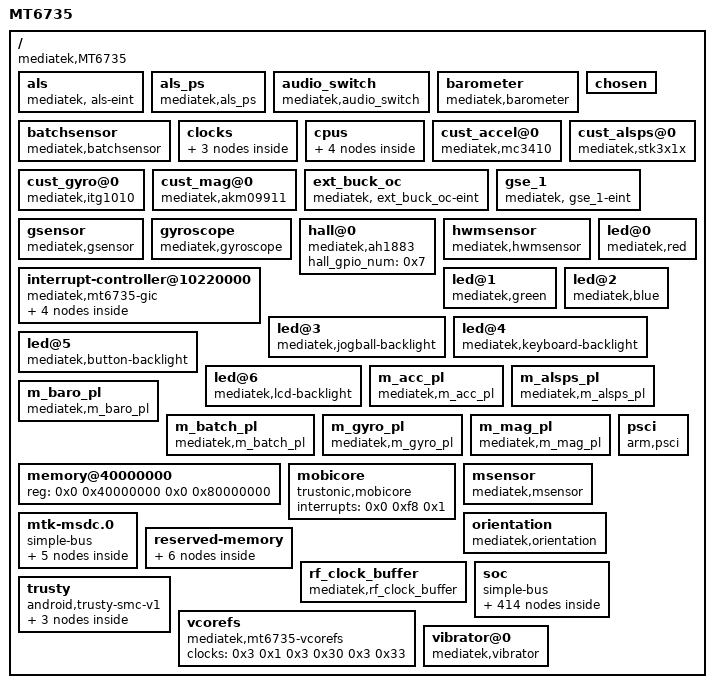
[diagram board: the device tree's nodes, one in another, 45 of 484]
/dts-v1/;

/ {
	#address-cells = <0x2>;
	#size-cells = <0x2>;
	compatible = "mediatek,MT6735";
	interrupt-parent = <0x1>;
	model = "MT6735";

	als {
		compatible = "mediatek, als-eint";
		debounce = <0x3 0x0>;
		interrupt-parent = <0xc>;
		interrupts = <0x3 0x8>;
		status = "okay";
	};

	als_ps {
		compatible = "mediatek,als_ps";
		pinctrl-0 = <0x90>;
		pinctrl-1 = <0x91>;
		pinctrl-names = "pin_default", "pin_cfg";
		status = "okay";
	};

	audio_switch {
		compatible = "mediatek,audio_switch";
	};

	barometer {
		compatible = "mediatek,barometer";
	};

	batchsensor {
		compatible = "mediatek,batchsensor";
	};

	chosen {
		bootargs = "console=tty0 console=ttyMT0,921600n1 root=/dev/ram initrd=0x44000000,0x300000 loglevel=8 androidboot.hardware=mt6735";
	};

	clocks {

		clk26m {
			#clock-cells = <0x0>;
			clock-frequency = <0x18cba80>;
			compatible = "fixed-clock";
			linux,phandle = <0x3b>;
			phandle = <0x3b>;
		};

		clk32k {
			#clock-cells = <0x0>;
			clock-frequency = <0x7d00>;
			compatible = "fixed-clock";
		};

		clk_null {
			#clock-cells = <0x0>;
			clock-frequency = <0x0>;
			compatible = "fixed-clock";
		};
	};

	cpus {
		#address-cells = <0x1>;
		#size-cells = <0x0>;

		cpu@000 {
			clock-frequency = "M|m";
			compatible = "arm,cortex-a53";
			cpu-release-addr = <0x0 0x40000200>;
			device_type = "cpu";
			enable-method = "spin-table";
			linux,phandle = <0xd>;
			phandle = <0xd>;
			reg = <0x0>;
		};

		cpu@001 {
			clock-frequency = "M|m";
			compatible = "arm,cortex-a53";
			cpu-release-addr = <0x0 0x40000200>;
			device_type = "cpu";
			enable-method = "spin-table";
			linux,phandle = <0xe>;
			phandle = <0xe>;
			reg = <0x1>;
		};

		cpu@002 {
			clock-frequency = "M|m";
			compatible = "arm,cortex-a53";
			cpu-release-addr = <0x0 0x40000200>;
			device_type = "cpu";
			enable-method = "spin-table";
			linux,phandle = <0xf>;
			phandle = <0xf>;
			reg = <0x2>;
		};

		cpu@003 {
			clock-frequency = "M|m";
			compatible = "arm,cortex-a53";
			cpu-release-addr = <0x0 0x40000200>;
			device_type = "cpu";
			enable-method = "spin-table";
			linux,phandle = <0x10>;
			phandle = <0x10>;
			reg = <0x3>;
		};
	};

	cust_accel@0 {
		compatible = "mediatek,mc3410";
		direction = <0x0>;
		firlen = <0x0>;
		i2c_addr = <0x4c 0x0 0x0 0x0>;
		i2c_num = <0x2>;
		is_batch_supported = <0x0>;
		power_id = <0xffff>;
		power_vol = <0x0>;
	};

	cust_alsps@0 {
		als_level = <0x5 0x9 0x24 0x3b 0x52 0x84 0xcd 0x111 0x1f4 0x34d 0x470 0x609 0x93c 0x122f 0x1b46>;
		als_value = <0xa 0xa 0x50 0x55 0x5a 0x91 0xe1 0x12c 0x226 0x3a2 0x4e2 0x6a4 0xa28 0x1400 0x1e00 0x2800>;
		compatible = "mediatek,stk3x1x";
		i2c_addr = <0x48 0x0 0x0 0x0>;
		i2c_num = <0x2>;
		is_batch_supported_als = <0x0>;
		is_batch_supported_ps = <0x0>;
		polling_mode_als = <0x1>;
		polling_mode_ps = <0x0>;
		power_id = <0xffff>;
		power_vol = <0x0>;
		ps_threshold_high = <0x6a4>;
		ps_threshold_low = <0x5dc>;
	};

	cust_gyro@0 {
		compatible = "mediatek,itg1010";
		direction = <0x3>;
		firlen = <0x0>;
		i2c_addr = <0x68 0x0 0x0 0x0>;
		i2c_num = <0x2>;
		is_batch_supported = <0x0>;
		power_id = <0xffff>;
		power_vol = <0x0>;
	};

	cust_mag@0 {
		compatible = "mediatek,akm09911";
		direction = <0x2>;
		i2c_addr = <0xd 0x0 0x0 0x0>;
		i2c_num = <0x2>;
		is_batch_supported = <0x0>;
		power_id = <0xffff>;
		power_vol = <0x0>;
	};

	ext_buck_oc {
		compatible = "mediatek, ext_buck_oc-eint";
		debounce = <0x4e 0x0>;
		interrupt-parent = <0xc>;
		interrupts = <0x4e 0x4>;
		status = "okay";
	};

	gse_1 {
		compatible = "mediatek, gse_1-eint";
		debounce = <0x42 0x0>;
		interrupt-parent = <0xc>;
		interrupts = <0x42 0x8>;
		status = "okay";
	};

	gsensor {
		compatible = "mediatek,gsensor";
	};

	gyroscope {
		compatible = "mediatek,gyroscope";
		debounce = <0x43 0x0>;
		interrupt-parent = <0xc>;
		interrupts = <0x43 0x8>;
		pinctrl-0 = <0x92>;
		pinctrl-1 = <0x93>;
		pinctrl-names = "pin_default", "pin_cfg";
		status = "okay";
	};

	hall@0 {
		compatible = "mediatek,ah1883";
		hall_gpio_num = <0x7>;
	};

	hwmsensor {
		compatible = "mediatek,hwmsensor";
	};

	interrupt-controller@10220000 {
		#address-cells = <0x0>;
		#interrupt-cells = <0x3>;
		compatible = "mediatek,mt6735-gic";
		interrupt-controller;
		linux,phandle = <0x1>;
		mediatek,wdt_irq = <0xa0>;
		phandle = <0x1>;
		reg = <0x0 0x10221000 0x0 0x1000 0x0 0x10222000 0x0 0x1000 0x0 0x10200620 0x0 0x1000>;

		gic-cpuif@0 {
			compatible = "arm,gic-cpuif";
			cpu = <0xd>;
			cpuif-id = <0x0>;
		};

		gic-cpuif@1 {
			compatible = "arm,gic-cpuif";
			cpu = <0xe>;
			cpuif-id = <0x1>;
		};

		gic-cpuif@2 {
			compatible = "arm,gic-cpuif";
			cpu = <0xf>;
			cpuif-id = <0x2>;
		};

		gic-cpuif@3 {
			compatible = "arm,gic-cpuif";
			cpu = <0x10>;
			cpuif-id = <0x3>;
		};
	};

	led@0 {
		compatible = "mediatek,red";
		data = <0x1>;
		led_mode = <0x0>;
		pwm_config = <0x0 0x0 0x0 0x0 0x0>;
	};

	led@1 {
		compatible = "mediatek,green";
		data = <0x1>;
		led_mode = <0x0>;
		pwm_config = <0x0 0x0 0x0 0x0 0x0>;
	};

	led@2 {
		compatible = "mediatek,blue";
		data = <0x1>;
		led_mode = <0x0>;
		pwm_config = <0x0 0x0 0x0 0x0 0x0>;
	};

	led@3 {
		compatible = "mediatek,jogball-backlight";
		data = <0x1>;
		led_mode = <0x0>;
		pwm_config = <0x0 0x0 0x0 0x0 0x0>;
	};

	led@4 {
		compatible = "mediatek,keyboard-backlight";
		data = <0x1>;
		led_mode = <0x0>;
		pwm_config = <0x0 0x0 0x0 0x0 0x0>;
	};

	led@5 {
		compatible = "mediatek,button-backlight";
		data = <0x1>;
		led_mode = <0x3>;
		pwm_config = <0x0 0x0 0x0 0x0 0x0>;
	};

	led@6 {
		compatible = "mediatek,lcd-backlight";
		data = <0x1>;
		led_mode = <0x5>;
		pwm_config = <0x0 0x0 0x0 0x0 0x0>;
	};

	m_acc_pl {
		compatible = "mediatek,m_acc_pl";
	};

	m_alsps_pl {
		compatible = "mediatek,m_alsps_pl";
	};

	m_baro_pl {
		compatible = "mediatek,m_baro_pl";
	};

	m_batch_pl {
		compatible = "mediatek,m_batch_pl";
	};

	m_gyro_pl {
		compatible = "mediatek,m_gyro_pl";
	};

	m_mag_pl {
		compatible = "mediatek,m_mag_pl";
	};

	memory@40000000 {
		device_type = "memory";
		reg = <0x0 0x40000000 0x0 0x80000000>;
	};

	mobicore {
		compatible = "trustonic,mobicore";
		interrupts = <0x0 0xf8 0x1>;
	};

	msensor {
		compatible = "mediatek,msensor";
	};

	mtk-msdc.0 {
		#address-cells = <0x1>;
		#size-cells = <0x1>;
		compatible = "simple-bus";
		ranges = <0x0 0x0 0x0 0xffffffff>;

		default {
			compatible = "mediatek, msdc1_ins-eint";
			debounce = <0x5 0x1f400>;
			interrupt-parent = <0xc>;
			interrupts = <0x5 0x4>;
			status = "okay";
		};

		msdc0@11230000 {
			bootable;
			bus-width = <0x8>;
			cap-mmc-highspeed;
			clk_src = [02];
			clock-names = "MSDC0-CLOCK", "MSDC0_PLL_SEL", "MSDC0_PLL_800M", "MSDC0_PLL_400M", "MSDC0_PLL_200M";
			clocks = <0x2 0xe 0x3 0xd 0x3 0x29 0x3 0x2b 0x3 0x2c>;
			compatible = "mediatek,mt6735-mmc";
			host_function = [00];
			interrupts = <0x0 0x4f 0x8>;
			max-frequency = <0xbebc200>;
			mmc-ddr-1_8v;
			mmc-hs200-1_8v;
			mmc-hs400-1_8v;
			msdc-sys-suspend;
			non-removable;
			pinctl = <0x4>;
			reg = <0x11230000 0x10000 0x10000e84 0x2>;
			register_setting = <0x5>;
			status = "okay";
		};

		msdc1@11240000 {
			bus-width = <0x4>;
			cap-sd-highspeed;
			cd-gpios = <0xb 0x5 0x0>;
			cd_level = [00];
			clk_src = [02];
			clock-names = "MSDC1-CLOCK";
			clocks = <0x2 0xf>;
			compatible = "mediatek,mt6735-mmc";
			host_function = [01];
			interrupts = <0x0 0x50 0x8>;
			max-frequency = <0xbebc200>;
			msdc-sys-suspend;
			pinctl = <0x6>;
			pinctl_ddr50 = <0x9>;
			pinctl_sdr104 = <0x7>;
			pinctl_sdr50 = <0x8>;
			reg = <0x11240000 0x10000 0x10000e84 0x2>;
			register_setting = <0xa>;
			sd-uhs-ddr50;
			sd-uhs-sdr104;
			sd-uhs-sdr12;
			sd-uhs-sdr25;
			sd-uhs-sdr50;
			status = "okay";
		};

		msdc2@11250000 {
			clock-names = "MSDC2-CLOCK";
			clocks = <0x2 0x10>;
			compatible = "mediatek,mt6735-mmc";
			interrupts = <0x0 0x51 0x8>;
			reg = <0x11250000 0x10000 0x10000e84 0x2>;
			status = "disabled";
		};

		msdc3@11260000 {
			clock-names = "MSDC3-CLOCK";
			clocks = <0x2 0x11>;
			compatible = "mediatek,mt6735-mmc";
			interrupts = <0x0 0x52 0x8>;
			reg = <0x11260000 0x10000 0x10000e84 0x2>;
			status = "disabled";
		};
	};

	orientation {
		compatible = "mediatek,orientation";
	};

	psci {
		affinity_info = <0x84000004>;
		compatible = "arm,psci";
		cpu_off = <0x84000002>;
		cpu_on = <0x84000003>;
		cpu_suspend = <0x84000001>;
		method = "smc";
	};

	reserved-memory {
		#address-cells = <0x2>;
		#size-cells = <0x2>;
		ranges;

		atf-reserved-memory@43000000 {
			compatible = "mediatek,mt6735-atf-reserved-memory", "mediatek,mt6735m-atf-reserved-memory", "mediatek,mt6753-atf-reserved-memory";
			no-map;
			reg = <0x0 0x43000000 0x0 0x30000>;
		};

		consys-reserve-memory {
			alignment = <0x0 0x200000>;
			compatible = "mediatek,consys-reserve-memory";
			no-map;
			size = <0x0 0x100000>;
		};

		minirdump-reserved-memory@43ff0000 {
			compatible = "mediatek,minirdump";
			reg = <0x0 0x43ff0000 0x0 0x10000>;
		};

		pstore-reserved-memory@43f10000 {
			compatible = "mediatek,pstore";
			reg = <0x0 0x43f10000 0x0 0xe0000>;
		};

		ram_console-reserved-memory@43f00000 {
			compatible = "mediatek,ram_console";
			reg = <0x0 0x43f00000 0x0 0x10000>;
		};

		reserve-memory-ccci_md1 {
			alignment = <0x0 0x2000000>;
			alloc-ranges = <0x0 0x40000000 0x0 0xc0000000>;
			compatible = "mediatek,reserve-memory-ccci_md1";
			no-map;
			size = <0x0 0x3810000>;
		};
	};

	rf_clock_buffer {
		compatible = "mediatek,rf_clock_buffer";
		mediatek,clkbuf-config = <0x2 0x2 0x2 0x2>;
		mediatek,clkbuf-quantity = <0x4>;
		status = "okay";
	};

	soc {
		#address-cells = <0x1>;
		#size-cells = <0x1>;
		compatible = "simple-bus";
		ranges = <0x0 0x0 0x0 0xffffffff>;

		BAT_NOTIFY {
			compatible = "mediatek,bat_notify";
		};

		accdet {
			accdet-mic-mode = <0x1>;
			accdet-mic-vol = <0x7>;
			accdet-plugout-debounce = <0x14>;
			compatible = "mediatek,mt6735-accdet";
			debounce = <0x6 0x3e800>;
			headset-four-key-threshold = <0x0 0x3a 0x79 0xc0 0x1c2>;
			headset-mode-setting = <0x500 0x200 0x1 0x1f0 0x800 0x800 0x20>;
			headset-three-key-threshold = <0x0 0x50 0xdc 0x1f4>;
			interrupt-parent = <0xc>;
			interrupts = <0x6 0x8>;
			pinctrl-0 = <0x63>;
			pinctrl-1 = <0x64>;
			pinctrl-names = "default", "state_eint_as_int1";
			status = "okay";
		};

		adc_hw@11001000 {
			clock-names = "auxadc-main";
			clocks = <0x2 0x1c>;
			compatible = "mediatek,mt6735-auxadc";
			interrupts = <0x0 0x4c 0x2>;
			reg = <0x11001000 0x1000>;

			adc_channel@ {
				compatible = "mediatek,adc_channel";
				mediatek,adc_fdd_rf_params_dynamic_custom_ch = <0xc>;
				mediatek,temperature0 = <0x0>;
				mediatek,temperature1 = <0x1>;
				status = "okay";
			};
		};

		apmixed@10209000 {
			compatible = "mediatek,apmixed";
			reg = <0x10209000 0x1000>;
		};

		apmixedsys@10209000 {
			#clock-cells = <0x1>;
			compatible = "mediatek,mt6735-apmixedsys";
			linux,phandle = <0x3a>;
			phandle = <0x3a>;
			reg = <0x10209000 0x1000>;
		};

		apuart0@11002000 {
			cell-index = <0x0>;
			clock-div = <0x1>;
			clock-frequency = <0x18cba80>;
			clock-names = "uart0-main", "uart-apdma";
			clocks = <0x2 0x12 0x2 0xd>;
			compatible = "mediatek,mt6735-uart";
			interrupts = <0x0 0x5b 0x8 0x0 0x67 0x8 0x0 0x68 0x8>;
			pinctrl-0 = <0x1f>;
			pinctrl-1 = <0x20>;
			pinctrl-2 = <0x21>;
			pinctrl-3 = <0x22>;
			pinctrl-4 = <0x23>;
			pinctrl-names = "uart0_gpio_default", "uart0_rx_set", "uart0_rx_clear", "uart0_tx_set", "uart0_tx_clear";
			reg = <0x11002000 0x1000 0x11000380 0x1000 0x11000400 0x80>;
			status = "okay";
		};

		apuart1@11003000 {
			cell-index = <0x1>;
			clock-div = <0x1>;
			clock-frequency = <0x18cba80>;
			clock-names = "uart1-main";
			clocks = <0x2 0x13>;
			compatible = "mediatek,mt6735-uart";
			interrupts = <0x0 0x5c 0x8 0x0 0x69 0x8 0x0 0x6a 0x8>;
			pinctrl-0 = <0x24>;
			pinctrl-1 = <0x25>;
			pinctrl-2 = <0x26>;
			pinctrl-3 = <0x27>;
			pinctrl-4 = <0x28>;
			pinctrl-names = "uart1_gpio_default", "uart1_rx_set", "uart1_rx_clear", "uart1_tx_set", "uart1_tx_clear";
			reg = <0x11003000 0x1000 0x11000480 0x80 0x11000500 0x80>;
			status = "okay";
		};

		apuart2@11004000 {
			cell-index = <0x2>;
			clock-div = <0x1>;
			clock-frequency = <0x18cba80>;
			clock-names = "uart2-main";
			clocks = <0x2 0x14>;
			compatible = "mediatek,mt6735-uart";
			interrupts = <0x0 0x5d 0x8 0x0 0x6b 0x8 0x0 0x6c 0x8>;
			pinctrl-0 = <0x29>;
			pinctrl-1 = <0x2a>;
			pinctrl-2 = <0x2b>;
			pinctrl-3 = <0x2c>;
			pinctrl-4 = <0x2d>;
			pinctrl-names = "uart2_gpio_default", "uart2_rx_set", "uart2_rx_clear", "uart2_tx_set", "uart2_tx_clear";
			reg = <0x11004000 0x1000 0x11000580 0x80 0x11000600 0x80>;
			status = "okay";
		};

		apuart3@11005000 {
			cell-index = <0x3>;
			clock-div = <0x1>;
			clock-frequency = <0x18cba80>;
			clock-names = "uart3-main";
			clocks = <0x2 0x15>;
			compatible = "mediatek,mt6735-uart";
			interrupts = <0x0 0x5e 0x8 0x0 0x6d 0x8 0x0 0x6e 0x8>;
			pinctrl-0 = <0x2e>;
			pinctrl-1 = <0x2f>;
			pinctrl-2 = <0x30>;
			pinctrl-3 = <0x31>;
			pinctrl-4 = <0x32>;
			pinctrl-names = "uart3_gpio_default", "uart3_rx_set", "uart3_rx_clear", "uart3_tx_set", "uart3_tx_clear";
			reg = <0x11005000 0x1000 0x11000680 0x80 0x11000700 0x80>;
			status = "okay";
		};

		apuart4@1100D000 {
			cell-index = <0x4>;
			clock-div = <0x1>;
			clock-frequency = <0x18cba80>;
			clock-names = "uart4-main";
			clocks = <0x2 0x16>;
			compatible = "mediatek,mt6735-uart";
			interrupts = <0x0 0x5f 0x8 0x0 0x6f 0x8 0x0 0x70 0x8>;
			reg = <0x1100d000 0x1000 0x11000780 0x80 0x11000800 0x80>;
		};

		apxgpt@10004000 {
			clock-frequency = <0xc65d40>;
			compatible = "mediatek,mt6735-apxgpt";
			interrupts = <0x0 0x98 0x8>;
			reg = <0x10004000 0x1000>;
		};

		audio@11220000 {
			compatible = "mediatek,audio";
			interrupts = <0x0 0x90 0x8>;
			reg = <0x11220000 0x10000>;
		};

		audiosys@11220000 {
			#clock-cells = <0x1>;
			compatible = "mediatek,mt6735-audiosys";
			linux,phandle = <0x39>;
			phandle = <0x39>;
			reg = <0x11220000 0x10000>;
		};

		bat_comm {
			ac_charger_current = <0x3d090>;
			apple_0_5a_charger_current = <0xc350>;
			apple_1_0a_charger_current = <0xfde8>;
			apple_2_1a_charger_current = <0x13880>;
			bat_low_temp_protect_enable = <0x0>;
			charging_full_current = <0x64>;
			charging_host_charger_current = <0xfde8>;
			compatible = "mediatek,battery";
			config_usb_if = <0x0>;
			err_charge_temperature = <0xff>;
			high_battery_voltage_support = <0x1>;
			max_charge_temperature = <0x46>;
			max_charge_temperature_minus_x_degree = <0x2f>;
			min_charge_temperature = <0x0>;
			min_charge_temperature_plus_x_degree = <0x6>;
			mtk_pump_express_plus_support = <0x1>;
			mtk_temperature_recharge_support = <0x1>;
			non_std_ac_charger_current = <0xc350>;
			npercent_tracking_time = <0x14>;
			onehundred_percent_tracking_time = <0xa>;
			recharging_voltage = <0x107c>;
			stop_charging_in_takling = <0x1>;
			sync_to_real_tracking_time = <0x3c>;
			ta_9v_support = <0x1>;
			ta_ac_7v_input_current = <0x30d40>;
			ta_ac_9v_input_current = <0x30d40>;
			ta_ac_charging_current = <0x3d090>;
			ta_start_battery_soc = <0x1>;
			ta_stop_battery_soc = <0x5f>;
			talking_recharge_voltage = <0xed8>;
			talking_sync_time = <0x3c>;
			usb_charger_current = <0xc350>;
			usb_charger_current_configured = <0xc350>;
			usb_charger_current_suspend = <0x0>;
			usb_charger_current_unconfigured = <0x1b58>;
			v_0percent_tracking = <0xd7a>;
			v_cc2topoff_thres = <0x1040>;
			v_charger_enable = <0x0>;
			v_charger_max = <0x2904>;
			v_charger_min = <0x1130>;
			v_pre2cc_thres = <0xd48>;
		};

		bat_meter {
			aging_tuning_value = <0x67>;
			batt_temperature_table = <0xffffffec 0x10a8d 0xfffffff1 0xd192 0xfffffff6 0xa60a 0xfffffffb 0x8464 0x0 0x6a53 0x5 0x5605 0xa 0x4606 0xf 0x3952 0x14 0x2f31 0x19 0x2710 0x1e 0x207b 0x23 0x1b24 0x28 0x16ca 0x2d 0x1335 0x32 0x1041 0x37 0xdcf 0x3c 0xbc6 0x41 0xa28 0x46 0x8ca>;
			batt_temperature_table_num = <0x13>;
			battery_profile_t0 = <0x0 0x10e4 0x2 0x10c2 0x4 0x10a8 0x6 0x1091 0x8 0x107c 0x9 0x1068 0xb 0x1054 0xd 0x1041 0xf 0x102e 0x11 0x101b 0x13 0x1009 0x15 0xffa 0x17 0xfed 0x18 0xfd9 0x1a 0xfba 0x1c 0xf9a 0x1e 0xf83 0x20 0xf71 0x22 0xf63 0x24 0xf57 0x26 0xf4b 0x27 0xf3f 0x29 0xf32 0x2b 0xf26 0x2d 0xf1a 0x2f 0xf0f 0x31 0xf04 0x33 0xefb 0x35 0xef2 0x36 0xeeb 0x38 0xee3 0x3a 0xedd 0x3c 0xed7 0x3e 0xed1 0x40 0xecd 0x42 0xeca 0x44 0xec7 0x45 0xec5 0x47 0xec2 0x49 0xebf 0x4b 0xebc 0x4d 0xeb8 0x4f 0xeb4 0x51 0xeaf 0x53 0xea8 0x54 0xea1 0x56 0xe97 0x58 0xe8e 0x5a 0xe83 0x5c 0xe79 0x5e 0xe70 0x60 0xe68 0x61 0xe61 0x62 0xe5a 0x63 0xe50 0x64 0xdc8 0x64 0xdac 0x64 0xdac 0x64 0xdac 0x64 0xdac 0x64 0xdac 0x64 0xdac 0x64 0xdac 0x64 0xdac 0x64 0xdac 0x64 0xdac 0x64 0xdac 0x64 0xdac 0x64 0xdac 0x64 0xdac 0x64 0xdac 0x64 0xdac 0x64 0xdac 0x64 0xdac 0x64 0xdac 0x64 0xdac 0x64 0xdac 0x64 0xdac 0x64 0xdac 0x64 0xdac 0x64 0xdac 0x64 0xdac 0x64 0xdac 0x64 0xdac 0x64 0xdac 0x64 0xdac 0x64 0xdac 0x64 0xdac 0x64 0xdac 0x64 0xdac 0x64 0xdac 0x64 0xdac 0x64 0xdac 0x64 0xdac 0x64 0xdac 0x64 0xdac 0x64 0xdac 0x64 0xdac 0x64 0xdac 0x64 0xdac>;
			battery_profile_t0_num = <0x64>;
			battery_profile_t1 = <0x0 0x10e9 0x2 0x10cd 0x4 0x10b4 0x6 0x10a0 0x7 0x108c 0x9 0x1078 0xb 0x1065 0xd 0x1052 0xf 0x103f 0x11 0x102c 0x12 0x1018 0x14 0x1006 0x16 0xff5 0x18 0xfea 0x1a 0xfdc 0x1c 0xfbc 0x1e 0xf98 0x1f 0xf82 0x21 0xf72 0x23 0xf66 0x25 0xf5b 0x27 0xf4e 0x29 0xf3f 0x2b 0xf31 0x2c 0xf23 0x2e 0xf16 0x30 0xf0b 0x32 0xf01 0x34 0xef8 0x36 0xef0 0x37 0xee8 0x39 0xee2 0x3b 0xedb 0x3d 0xed5 0x3f 0xed0 0x41 0xecb 0x43 0xec7 0x44 0xec3 0x46 0xec0 0x48 0xebe 0x4a 0xeba 0x4c 0xeb7 0x4e 0xeb2 0x4f 0xead 0x51 0xea6 0x53 0xe9e 0x55 0xe93 0x57 0xe89 0x59 0xe7b 0x5b 0xe72 0x5c 0xe6e 0x5e 0xe69 0x60 0xe5c 0x62 0xe28 0x64 0xdbb 0x64 0xdac 0x64 0xdac 0x64 0xdac 0x64 0xdac 0x64 0xdac 0x64 0xdac 0x64 0xdac 0x64 0xdac 0x64 0xdac 0x64 0xdac 0x64 0xdac 0x64 0xdac 0x64 0xdac 0x64 0xdac 0x64 0xdac 0x64 0xdac 0x64 0xdac 0x64 0xdac 0x64 0xdac 0x64 0xdac 0x64 0xdac 0x64 0xdac 0x64 0xdac 0x64 0xdac 0x64 0xdac 0x64 0xdac 0x64 0xdac 0x64 0xdac 0x64 0xdac 0x64 0xdac 0x64 0xdac 0x64 0xdac 0x64 0xdac 0x64 0xdac 0x64 0xdac 0x64 0xdac 0x64 0xdac 0x64 0xdac 0x64 0xdac 0x64 0xdac 0x64 0xdac 0x64 0xdac 0x64 0xdac 0x64 0xdac 0x64 0xdac>;
			battery_profile_t1_num = <0x64>;
			battery_profile_t2 = <0x0 0x10f1 0x2 0x10d8 0x4 0x10c1 0x5 0x10ac 0x7 0x1097 0x9 0x1083 0xb 0x106e 0xd 0x105b 0xf 0x1047 0x10 0x1034 0x12 0x1021 0x14 0x100e 0x16 0xffb 0x18 0xfe9 0x19 0xfde 0x1b 0xfcf 0x1d 0xfb1 0x1f 0xf98 0x21 0xf8b 0x23 0xf84 0x24 0xf79 0x26 0xf6b 0x28 0xf5d 0x2a 0xf4c 0x2c 0xf37 0x2d 0xf24 0x2f 0xf16 0x31 0xf0a 0x33 0xf00 0x35 0xef7 0x37 0xeef 0x38 0xee8 0x3a 0xee1 0x3c 0xeda 0x3e 0xed5 0x40 0xecf 0x41 0xeca 0x43 0xec6 0x45 0xec1 0x47 0xebc 0x49 0xeb5 0x4b 0xead 0x4c 0xea8 0x4e 0xea1 0x50 0xe9b 0x52 0xe96 0x54 0xe8e 0x55 0xe83 0x57 0xe79 0x59 0xe6b 0x5b 0xe64 0x5d 0xe62 0x5f 0xe61 0x60 0xe58 0x62 0xe1b 0x64 0xdac 0x64 0xdac 0x64 0xdac 0x64 0xdac 0x64 0xdac 0x64 0xdac 0x64 0xdac 0x64 0xdac 0x64 0xdac 0x64 0xdac 0x64 0xdac 0x64 0xdac 0x64 0xdac 0x64 0xdac 0x64 0xdac 0x64 0xdac 0x64 0xdac 0x64 0xdac 0x64 0xdac 0x64 0xdac 0x64 0xdac 0x64 0xdac 0x64 0xdac 0x64 0xdac 0x64 0xdac 0x64 0xdac 0x64 0xdac 0x64 0xdac 0x64 0xdac 0x64 0xdac 0x64 0xdac 0x64 0xdac 0x64 0xdac 0x64 0xdac 0x64 0xdac 0x64 0xdac 0x64 0xdac 0x64 0xdac 0x64 0xdac 0x64 0xdac 0x64 0xdac 0x64 0xdac 0x64 0xdac 0x64 0xdac 0x64 0xdac>;
			battery_profile_t2_num = <0x64>;
			battery_profile_t3 = <0x0 0x10d9 0x2 0x10c2 0x4 0x10ad 0x6 0x1098 0x8 0x1083 0x9 0x106f 0xb 0x105a 0xd 0x1046 0xf 0x1033 0x11 0x101f 0x13 0x100c 0x15 0xff9 0x17 0xfe7 0x19 0xfd5 0x1a 0xfc4 0x1c 0xfb3 0x1e 0xfa2 0x20 0xf93 0x22 0xf83 0x24 0xf73 0x26 0xf63 0x28 0xf50 0x29 0xf3c 0x2b 0xf2a 0x2d 0xf1c 0x2f 0xf11 0x31 0xf06 0x33 0xefd 0x35 0xef4 0x37 0xeec 0x39 0xee4 0x3a 0xedd 0x3c 0xed7 0x3e 0xed0 0x40 0xecb 0x42 0xec6 0x44 0xec0 0x46 0xeba 0x48 0xeae 0x4a 0xea4 0x4b 0xe9d 0x4d 0xe95 0x4f 0xe8e 0x51 0xe89 0x53 0xe81 0x55 0xe76 0x57 0xe6c 0x59 0xe5f 0x5b 0xe59 0x5c 0xe58 0x5e 0xe56 0x60 0xe4d 0x62 0xe15 0x64 0xdb2 0x64 0xdac 0x64 0xdac 0x64 0xdac 0x64 0xdac 0x64 0xdac 0x64 0xdac 0x64 0xdac 0x64 0xdac 0x64 0xdac 0x64 0xdac 0x64 0xdac 0x64 0xdac 0x64 0xdac 0x64 0xdac 0x64 0xdac 0x64 0xdac 0x64 0xdac 0x64 0xdac 0x64 0xdac 0x64 0xdac 0x64 0xdac 0x64 0xdac 0x64 0xdac 0x64 0xdac 0x64 0xdac 0x64 0xdac 0x64 0xdac 0x64 0xdac 0x64 0xdac 0x64 0xdac 0x64 0xdac 0x64 0xdac 0x64 0xdac 0x64 0xdac 0x64 0xdac 0x64 0xdac 0x64 0xdac 0x64 0xdac 0x64 0xdac 0x64 0xdac 0x64 0xdac 0x64 0xdac 0x64 0xdac 0x64 0xdac 0x64 0xdac 0x64 0xdac>;
			battery_profile_t3_num = <0x64>;
			car_tune_value = <0x5f>;
			change_tracking_point = <0x1>;
			close_poweroff_wakeup_period = <0x1e>;
			compatible = "mediatek,bat_meter";
			current_detect_r_fg = <0xa>;
			cust_hw_cc = <0x0>;
			cust_poweron_delta_capacity_tolrance = <0x1e>;
			cust_poweron_delta_hw_sw_ocv_capacity_tolrance = <0xa>;
			cust_poweron_delta_vbat_tolrance = <0x1e>;
			cust_poweron_low_capacity_tolrance = <0x5>;
			cust_poweron_max_vbat_tolrance = <0x5a>;
			cust_r_fg_offset = <0x0>;
			cust_r_sense = <0x44>;
			cust_tracking_point = <0x1>;
			fg_meter_resistance = <0x0>;
			fg_vbat_average_size = <0x12>;
			fixed_tbat_25 = <0x0>;
			low_power_wakeup_period = <0x12c>;
			minerroroffset = <0x3e8>;
			normal_wakeup_period = <0x1518>;
			oam_d5 = <0x1>;
			ocv_board_compesate = <0x0>;
			q_max_neg_10 = <0x11e3>;
			q_max_neg_10_h_current = <0xdd0>;
			q_max_pos_0 = <0x13b2>;
			q_max_pos_0_h_current = <0x1279>;
			q_max_pos_25 = <0x13ec>;
			q_max_pos_25_h_current = <0x13ba>;
			q_max_pos_50 = <0x1359>;
			q_max_pos_50_h_current = <0x132f>;
			r_bat_sense = <0x4>;
			r_charger_1 = <0x14a>;
			r_charger_2 = <0x27>;
			r_fg_board_base = <0x3e8>;
			r_fg_board_slope = <0x3e8>;
			r_fg_value = <0xa>;
			r_i_sense = <0x4>;
			r_profile_t0 = <0x351 0x10e4 0x351 0x10c2 0x34b 0x10a8 0x344 0x1091 0x334 0x107c 0x32b 0x1068 0x31f 0x1054 0x315 0x1041 0x30c 0x102e 0x301 0x101b 0x2f7 0x1009 0x2f4 0xffa 0x2f5 0xfed 0x2ed 0xfd9 0x2d0 0xfba 0x2b2 0xf9a 0x2a5 0xf83 0x29f 0xf71 0x29c 0xf63 0x29c 0xf57 0x296 0xf4b 0x28d 0xf3f 0x28d 0xf32 0x287 0xf26 0x283 0xf1a 0x27e 0xf0f 0x27e 0xf04 0x27e 0xefb 0x27e 0xef2 0x27e 0xeeb 0x281 0xee3 0x283 0xedd 0x286 0xed7 0x289 0xed1 0x28e 0xecd 0x295 0xeca 0x29f 0xec7 0x2af 0xec5 0x2bb 0xec2 0x2cb 0xebf 0x2da 0xebc 0x2ea 0xeb8 0x303 0xeb4 0x31b 0xeaf 0x337 0xea8 0x352 0xea1 0x379 0xe97 0x3a2 0xe8e 0x3d4 0xe83 0x67 0xe79 0x6e 0xe70 0x77 0xe68 0x78 0xe61 0x76 0xe5a 0x74 0xe50 0x335 0xdc8 0x335 0xdac 0x335 0xdac 0x335 0xdac 0x335 0xdac 0x335 0xdac 0x335 0xdac 0x335 0xdac 0x335 0xdac 0x335 0xdac 0x335 0xdac 0x335 0xdac 0x335 0xdac 0x335 0xdac 0x335 0xdac 0x335 0xdac 0x335 0xdac 0x335 0xdac 0x335 0xdac 0x335 0xdac 0x335 0xdac 0x335 0xdac 0x335 0xdac 0x335 0xdac 0x335 0xdac 0x335 0xdac 0x335 0xdac 0x335 0xdac 0x335 0xdac 0x335 0xdac 0x335 0xdac 0x335 0xdac 0x335 0xdac 0x335 0xdac 0x335 0xdac 0x335 0xdac 0x335 0xdac 0x335 0xdac 0x335 0xdac 0x335 0xdac 0x335 0xdac 0x335 0xdac 0x335 0xdac 0x335 0xdac 0x335 0xdac>;
			r_profile_t0_num = <0x64>;
			r_profile_t1 = <0x198 0x10e9 0x198 0x10cd 0x193 0x10b4 0x18d 0x10a0 0x186 0x108c 0x17e 0x1078 0x178 0x1065 0x173 0x1052 0x170 0x103f 0x16d 0x102c 0x169 0x1018 0x167 0x1006 0x166 0xff5 0x16d 0xfea 0x173 0xfdc 0x164 0xfbc 0x153 0xf98 0x14d 0xf82 0x149 0xf72 0x148 0xf66 0x147 0xf5b 0x13f 0xf4e 0x138 0xf3f 0x130 0xf31 0x12b 0xf23 0x128 0xf16 0x127 0xf0b 0x125 0xf01 0x126 0xef8 0x127 0xef0 0x128 0xee8 0x129 0xee2 0x12b 0xedb 0x12d 0xed5 0x12e 0xed0 0x130 0xecb 0x133 0xec7 0x137 0xec3 0x139 0xec0 0x138 0xebe 0x13c 0xeba 0x140 0xeb7 0x147 0xeb2 0x14c 0xead 0x154 0xea6 0x15c 0xe9e 0x166 0xe93 0x176 0xe89 0x188 0xe7b 0x19c 0xe72 0x1ba 0xe6e 0x1e6 0xe69 0x227 0xe5c 0x264 0xe28 0x2d7 0xdbb 0x2d7 0xdac 0x2d7 0xdac 0x2d7 0xdac 0x2d7 0xdac 0x2d7 0xdac 0x2d7 0xdac 0x2d7 0xdac 0x2d7 0xdac 0x2d7 0xdac 0x2d7 0xdac 0x2d7 0xdac 0x2d7 0xdac 0x2d7 0xdac 0x2d7 0xdac 0x2d7 0xdac 0x2d7 0xdac 0x2d7 0xdac 0x2d7 0xdac 0x2d7 0xdac 0x2d7 0xdac 0x2d7 0xdac 0x2d7 0xdac 0x2d7 0xdac 0x2d7 0xdac 0x2d7 0xdac 0x2d7 0xdac 0x2d7 0xdac 0x2d7 0xdac 0x2d7 0xdac 0x2d7 0xdac 0x2d7 0xdac 0x2d7 0xdac 0x2d7 0xdac 0x2d7 0xdac 0x2d7 0xdac 0x2d7 0xdac 0x2d7 0xdac 0x2d7 0xdac 0x2d7 0xdac 0x2d7 0xdac 0x2d7 0xdac 0x2d7 0xdac 0x2d7 0xdac 0x2d7 0xdac 0x2d7 0xdac>;
			r_profile_t1_num = <0x64>;
			r_profile_t2 = <0x7c 0x10f1 0x7c 0x10d8 0x7d 0x10c1 0x7b 0x10ac 0x7a 0x1097 0x7a 0x1083 0x7a 0x106e 0x7a 0x105b 0x79 0x1047 0x7b 0x1034 0x7d 0x1021 0x7c 0x100e 0x7c 0xffb 0x7c 0xfe9 0x85 0xfde 0x84 0xfcf 0x7d 0xfb1 0x7e 0xf98 0x80 0xf8b 0x88 0xf84 0x89 0xf79 0x8b 0xf6b 0x8d 0xf5d 0x8a 0xf4c 0x81 0xf37 0x7a 0xf24 0x77 0xf16 0x75 0xf0a 0x74 0xf00 0x74 0xef7 0x74 0xeef 0x75 0xee8 0x74 0xee1 0x73 0xeda 0x74 0xed5 0x74 0xecf 0x75 0xeca 0x76 0xec6 0x77 0xec1 0x77 0xebc 0x74 0xeb5 0x71 0xead 0x74 0xea8 0x74 0xea1 0x74 0xe9b 0x77 0xe96 0x76 0xe8e 0x76 0xe83 0x77 0xe79 0x77 0xe6b 0x74 0xe64 0x78 0xe62 0x81 0xe61 0x8c 0xe58 0x87 0xe1b 0x91 0xdac 0x91 0xdac 0x91 0xdac 0x91 0xdac 0x91 0xdac 0x91 0xdac 0x91 0xdac 0x91 0xdac 0x91 0xdac 0x91 0xdac 0x91 0xdac 0x91 0xdac 0x91 0xdac 0x91 0xdac 0x91 0xdac 0x91 0xdac 0x91 0xdac 0x91 0xdac 0x91 0xdac 0x91 0xdac 0x91 0xdac 0x91 0xdac 0x91 0xdac 0x91 0xdac 0x91 0xdac 0x91 0xdac 0x91 0xdac 0x91 0xdac 0x91 0xdac 0x91 0xdac 0x91 0xdac 0x91 0xdac 0x91 0xdac 0x91 0xdac 0x91 0xdac 0x91 0xdac 0x91 0xdac 0x91 0xdac 0x91 0xdac 0x91 0xdac 0x91 0xdac 0x91 0xdac 0x91 0xdac 0x91 0xdac 0x91 0xdac>;
			r_profile_t2_num = <0x64>;
			r_profile_t3 = <0x66 0x10d9 0x66 0x10c2 0x66 0x10ad 0x67 0x1098 0x67 0x1083 0x67 0x106f 0x66 0x105a 0x67 0x1046 0x67 0x1033 0x68 0x101f 0x68 0x100c 0x68 0xff9 0x69 0xfe7 0x6a 0xfd5 0x6c 0xfc4 0x6c 0xfb3 0x6d 0xfa2 0x70 0xf93 0x71 0xf83 0x73 0xf73 0x76 0xf63 0x74 0xf50 0x6d 0xf3c 0x69 0xf2a 0x67 0xf1c 0x68 0xf11 0x67 0xf06 0x67 0xefd 0x67 0xef4 0x66 0xeec 0x67 0xee4 0x68 0xedd 0x68 0xed7 0x69 0xed0 0x6a 0xecb 0x6c 0xec6 0x6d 0xec0 0x6d 0xeba 0x67 0xeae 0x68 0xea4 0x69 0xe9d 0x68 0xe95 0x67 0xe8e 0x6a 0xe89 0x6b 0xe81 0x69 0xe76 0x6b 0xe6c 0x67 0xe5f 0x66 0xe59 0x6d 0xe58 0x76 0xe56 0x7e 0xe4d 0x72 0xe15 0x77 0xdb2 0x89 0xdac 0x89 0xdac 0x89 0xdac 0x89 0xdac 0x89 0xdac 0x89 0xdac 0x89 0xdac 0x89 0xdac 0x89 0xdac 0x89 0xdac 0x89 0xdac 0x89 0xdac 0x89 0xdac 0x89 0xdac 0x89 0xdac 0x89 0xdac 0x89 0xdac 0x89 0xdac 0x89 0xdac 0x89 0xdac 0x89 0xdac 0x89 0xdac 0x89 0xdac 0x89 0xdac 0x89 0xdac 0x89 0xdac 0x89 0xdac 0x89 0xdac 0x89 0xdac 0x89 0xdac 0x89 0xdac 0x89 0xdac 0x89 0xdac 0x89 0xdac 0x89 0xdac 0x89 0xdac 0x89 0xdac 0x89 0xdac 0x89 0xdac 0x89 0xdac 0x89 0xdac 0x89 0xdac 0x89 0xdac 0x89 0xdac 0x89 0xdac 0x89 0xdac>;
			r_profile_t3_num = <0x64>;
			rbat_pull_up_r = <0x4204>;
			rbat_pull_up_volt = <0x708>;
			temperature_t = <0xff>;
			temperature_t0 = <0x6e>;
			temperature_t1 = <0x0>;
			temperature_t2 = <0x19>;
			temperature_t3 = <0x32>;
			vbat_low_power_wakeup = <0xdac>;
			vbat_normal_wakeup = <0xe10>;
		};

		btcvsd@18000000 {
			compatible = "mediatek,audio_bt_cvsd";
			interrupts = <0x0 0xe4 0x8>;
			offset = <0x700 0x800 0xfd0 0xfd4 0xfd8>;
			reg = <0x10000000 0x1000 0x18000000 0x10000 0x18080000 0x8000>;
		};

		btif@1100c000 {
			clock-names = "btifc", "apdmac";
			clocks = <0x2 0x17 0x2 0xd>;
			compatible = "mediatek,btif";
			interrupts = <0x0 0x5a 0x8>;
			reg = <0x1100c000 0x1000>;
		};

		btif_rx@11000900 {
			compatible = "mediatek,btif_rx";
			interrupts = <0x0 0x72 0x8>;
			reg = <0x11000900 0x80>;
		};

		btif_tx@11000880 {
			compatible = "mediatek,btif_tx";
			interrupts = <0x0 0x71 0x8>;
			reg = <0x11000880 0x80>;
		};

		bus_dbg@10208000 {
			compatible = "mediatek,bus_dbg-v1";
			interrupts = <0x0 0x89 0x8>;
			reg = <0x10208000 0x1000>;
		};

		c2k_sdio {
			compatible = "mediatek,mt6735-c2k_sdio";
			interrupts = <0x0 0xe6 0x8>;
		};

		ccci_off {
			clock-names = "scp-sys-md1-main";
			clocks = <0x11 0x1>;
			compatible = "mediatek,ccci_off";
		};

		chipid@08000000 {
			compatible = "mediatek,chipid";
			reg = <0x8000000 0x4 0x8000004 0x4 0x8000008 0x4 0x800000c 0x4>;
		};

		cksys@10210000 {
			compatible = "mediatek,cksys";
			reg = <0x10210000 0x1000>;
		};

		consys@18070000 {
			clock-names = "conn", "bus";
			clocks = <0x11 0x3 0x17 0xb>;
			compatible = "mediatek,mt6735-consys";
			interrupts = <0x0 0xe3 0x8 0x0 0xe1 0x8>;
			pinctrl-0 = <0x58>;
			pinctrl-1 = <0x59>;
			pinctrl-2 = <0x5a>;
			pinctrl-3 = <0x5b>;
			pinctrl-names = "default", "gps_lna_state_init", "gps_lna_state_oh", "gps_lna_state_ol";
			reg = <0x18070000 0x200 0x10212000 0x100 0x10000000 0x2000 0x10006000 0x1000>;
			status = "okay";
			vcn18-supply = <0x54>;
			vcn28-supply = <0x55>;
			vcn33_bt-supply = <0x56>;
			vcn33_wifi-supply = <0x57>;
		};

		cpu_dbgapb@0x10810000 {
			compatible = "mediatek,mt6735-dbg_debug";
			num = <0x4>;
			reg = <0x10810000 0x1000 0x10910000 0x1000 0x10a10000 0x1000 0x10b10000 0x1000>;
		};

		cpuxgpt@10200000 {
			compatible = "mediatek,mt6735-cpuxgpt";
			interrupts = <0x0 0x40 0x4 0x0 0x41 0x4 0x0 0x42 0x4 0x0 0x43 0x4 0x0 0x44 0x4 0x0 0x45 0x4 0x0 0x46 0x4 0x0 0x47 0x4>;
			reg = <0x10200000 0x1000>;
		};

		cqdma@10217c00 {
			compatible = "mediatek,cqdma";
			interrupts = <0x0 0x97 0x8>;
			nr_channel = <0x1>;
			reg = <0x10217c00 0xc00>;
		};

		dbgapb_base@1011a000 {
			compatible = "mediatek,dbgapb_base";
			reg = <0x1011a000 0x100>;
		};

		ddrphy@10213000 {
			compatible = "mediatek,mt6735-ddrphy";
			reg = <0x10213000 0x1000>;
		};

		devapc@10207000 {
			clock-names = "devapc-main";
			clocks = <0x17 0x5>;
			compatible = "mediatek,devapc";
			interrupts = <0x0 0x86 0x8>;
			reg = <0x10207000 0x1000>;
		};

		devapc_ao@10007000 {
			compatible = "mediatek,devapc_ao";
			reg = <0x10007000 0x1000>;
		};

		dispsys@14007000 {
			clock-names = "DISP0_SMI_COMMON", "DISP0_SMI_LARB0", "DISP0_DISP_OVL0", "DISP0_DISP_RDMA0", "DISP0_DISP_RDMA1", "DISP0_DISP_WDMA0", "DISP0_DISP_COLOR", "DISP0_DISP_CCORR", "DISP0_DISP_AAL", "DISP0_DISP_GAMMA", "DISP0_DISP_DITHER", "DISP1_DSI_ENGINE", "DISP1_DSI_DIGITAL", "DISP1_DPI_ENGINE", "DISP1_DPI_PIXEL", "DISP_PWM", "MUX_DPI0", "TVDPLL_CK", "TVDPLL_D2", "DPI_CK", "MUX_DISPPWM", "UNIVPLL2_D4", "SYSPLL4_D2_D8", "AD_SYS_26M_CK", "DISP_MTCMOS_CLK";
			clocks = <0x18 0x1 0x18 0x2 0x18 0xb 0x18 0xc 0x18 0xd 0x18 0xe 0x18 0xf 0x18 0x10 0x18 0x11 0x18 0x12 0x18 0x13 0x18 0x14 0x18 0x15 0x18 0x16 0x18 0x17 0x2 0x1 0x3 0x16 0x3 0x3c 0x3 0x3d 0x3 0x4d 0x3 0x1d 0x3 0x45 0x3 0x3a 0x3 0x22 0x11 0x4>;
			compatible = "mediatek,mt6735-dispsys";
			interrupts = <0x0 0xc1 0x8 0x0 0x0 0x8 0x0 0xc2 0x8 0x0 0xc3 0x8 0x0 0xc4 0x8 0x0 0xc5 0x8 0x0 0xc6 0x8 0x0 0xc7 0x8 0x0 0xc8 0x8 0x0 0xc9 0x8 0x0 0x0 0x8 0x0 0x75 0x8 0x0 0x0 0x8 0x0 0xba 0x8 0x0 0xcb 0x8 0x0 0xcc 0x8 0x0 0xcd 0x8 0x0 0xb0 0x8 0x0 0x0 0x8 0x0 0x0 0x8 0x0 0x0 0x8 0x0 0x0 0x8 0x0 0x0 0x8 0x0 0x0 0x8 0x0 0x0 0x8 0x0 0x0 0x8 0x0 0x0 0x8 0x0 0x0 0x8>;
			reg = <0x14007000 0x1000 0x0 0x0 0x14008000 0x1000 0x14009000 0x1000 0x1400a000 0x1000 0x1400b000 0x1000 0x1400c000 0x1000 0x1400d000 0x1000 0x1400e000 0x1000 0x1400f000 0x1000 0x0 0x0 0x1100e000 0x1000 0x0 0x0 0x14014000 0x1000 0x14011000 0x1000 0x14012000 0x1000 0x14000000 0x1000 0x14015000 0x1000 0x14016000 0x1000 0x14017000 0x1000 0x10206000 0x1000 0x10210000 0x1000 0x10211a70 0xc 0x10211974 0xc 0x10211b70 0xc 0x10206044 0xc 0x10206514 0xc 0x10206558 0xc 0x102100a0 0x1000 0x10209270 0x1000 0x10209274 0x1000 0x0 0x0 0x10209000 0x1000>;
		};

		dma@11000000 {
			compatible = "mediatek,ap_dma";
			interrupts = <0x0 0x72 0x8>;
			reg = <0x11000000 0x1000>;
		};

		dramc@10214000 {
			clock-names = "infra-cqdma";
			clocks = <0x17 0x2>;
			compatible = "mediatek,mt6735-dramc";
			reg = <0x10214000 0x1000>;
		};

		dramc_nao@1020e000 {
			compatible = "mediatek,mt6735-dramc_nao";
			reg = <0x1020e000 0x1000>;
		};

		dsi_te {
			compatible = "mediatek, dsi_te_1-eint";
			status = "disabled";
		};

		efusec@10206000 {
			compatible = "mediatek,efusec";
			reg = <0x10206000 0x1000>;
		};

		eintc@10005000 {
			#interrupt-cells = <0x2>;
			compatible = "mediatek,mt-eic";
			interrupt-controller;
			interrupts = <0x0 0x99 0x4>;
			linux,phandle = <0xc>;
			mediatek,mapping_table_entry = <0x0>;
			mediatek,max_eint_num = <0xd5>;
			phandle = <0xc>;
			reg = <0x10005000 0x1000>;

			MD1_SIM1_HOT_PLUG_EINT@0 {
				compatible = "mediatek,MD1_SIM1_HOT_PLUG_EINT-eint";
				debounce = <0x0 0x0>;
				dedicated = <0x0 0x0>;
				interrupts = <0x0 0x4>;
				sockettype = <0x0 0x0>;
				src_pin = <0x0 0x1>;
				status = "okay";
			};

			MD1_SIM2_HOT_PLUG_EINT@1 {
				compatible = "mediatek,MD1_SIM2_HOT_PLUG_EINT-eint";
				debounce = <0x1 0x0>;
				dedicated = <0x1 0x0>;
				interrupts = <0x1 0x4>;
				sockettype = <0x1 0x0>;
				src_pin = <0x1 0x1>;
				status = "okay";
			};

			pmic@206 {
				compatible = "mediatek, pmic-eint";
				debounce = <0xce 0x3e8>;
				interrupt-parent = <0xc>;
				interrupts = <0xce 0x4>;
			};
		};

		emi@10203000 {
			compatible = "mediatek,emi";
			interrupts = <0x0 0x88 0x4>;
			reg = <0x10203000 0x1000>;
		};

		fdvt@1500b000 {
			clock-names = "FD-SCP_SYS_DIS", "FD-SCP_SYS_ISP", "FD-MM_DISP0_SMI_COMMON", "FD-IMG_IMAGE_FD";
			clocks = <0x11 0x4 0x11 0x6 0x18 0x1 0x1a 0x8>;
			compatible = "mediatek,fdvt";
			interrupts = <0x0 0xd0 0x8>;
			reg = <0x1500b000 0x1000>;
		};

		fhctl@10209f00 {
			compatible = "mediatek,fhctl";
			reg = <0x10209f00 0x100>;
		};

		fingerprint {
			compatible = "mediatek,gf518m";
			debounce = <0x4 0x0>;
			interrupt-parent = <0xc>;
			interrupts = <0x4 0x2>;
			pinctrl-0 = <0x6c>;
			pinctrl-1 = <0x6d>;
			pinctrl-2 = <0x6e>;
			pinctrl-3 = <0x6f>;
			pinctrl-names = "fingerprint_default", "fingerprint_pin_irq", "fingerprint_reset_high", "fingerprint_reset_low";
			status = "okay";
		};

		g3d_config@13000000 {
			compatible = "mediatek,g3d_config";
			reg = <0x13000000 0x1000>;
		};

		gce@10217000 {
			apxgpt2_count = <0x10004028>;
			audio_base = <0x11220000 0x12 0xffff0000>;
			buf_underrun_event_0 = <0x2d>;
			buf_underrun_event_1 = <0x2e>;
			camsv_1_pass1_done = <0x47>;
			camsv_2_pass1_done = <0x46>;
			clock-names = "GCE";
			clocks = <0x17 0x2>;
			compatible = "mediatek,gce";
			conn_peri_base = <0x18000000 0x7 0xffff0000>;
			disp_aal_frame_done = <0x1e>;
			disp_aal_sof = <0xc>;
			disp_ccorr_frame_done = <0x1c>;
			disp_ccorr_sof = <0xa>;
			disp_color_frame_done = <0x1d>;
			disp_color_sof = <0xb>;
			disp_dither_base = <0x14010000 0x2 0xffff0000>;
			disp_dither_frame_done = <0x20>;
			disp_dither_sof = <0xe>;
			disp_dpi0_frame_done = <0x22>;
			disp_gamma_frame_done = <0x1f>;
			disp_gamma_sof = <0xd>;
			disp_mutex_reg = <0x14014000 0x1000>;
			disp_ovl0_frame_done = <0x18>;
			disp_ovl0_sof = <0x6>;
			disp_pwm0_sof = <0x10>;
			disp_rdma0_frame_done = <0x19>;
			disp_rdma0_sof = <0x7>;
			disp_rdma1_frame_done = <0x1a>;
			disp_rdma1_sof = <0x8>;
			disp_wdma0_frame_done = <0x1b>;
			disp_wdma0_sof = <0x9>;
			dsi0_te_event = <0x3>;
			g3d_config_base = <0x13000000 0x0 0xffff0000>;
			gcpu_base = <0x10210000 0xf 0xffff0000>;
			imgsys_base = <0x15000000 0x4 0xffff0000>;
			infra_na3_base = <0x10030000 0xb 0xffff0000>;
			infra_na4_base = <0x10040000 0xc 0xffff0000>;
			interrupts = <0x0 0x97 0x8 0x0 0x94 0x8>;
			isp_frame_done_p1_0 = <0x45>;
			isp_frame_done_p1_1 = <0x44>;
			isp_frame_done_p2_0 = <0x43>;
			isp_frame_done_p2_1 = <0x42>;
			isp_frame_done_p2_2 = <0x41>;
			jpgdec_done = <0x83>;
			jpgenc_done = <0x82>;
			kp_base = <0x10010000 0x9 0xffff0000>;
			mcucfg_base = <0x10200000 0xe 0xffff0000>;
			mdp_rdma0_frame_done = <0x11>;
			mdp_rdma0_sof = <0x0>;
			mdp_rsz0_frame_done = <0x12>;
			mdp_rsz0_sof = <0x1>;
			mdp_rsz1_frame_done = <0x13>;
			mdp_rsz1_sof = <0x2>;
			mdp_tdshp_frame_done = <0x14>;
			mdp_tdshp_sof = <0x2f>;
			mdp_wdma_frame_done = <0x15>;
			mdp_wdma_sof = <0x4>;
			mdp_wrot_read_frame_done = <0x17>;
			mdp_wrot_sof = <0x5>;
			mdp_wrot_write_frame_done = <0x16>;
			mm_na_base = <0x14020000 0x3 0xffff0000>;
			mmsys_config_base = <0x14000000 0x1 0xffff0000>;
			msdc0_base = <0x11230000 0x13 0xffff0000>;
			msdc1_base = <0x11240000 0x14 0xffff0000>;
			msdc2_base = <0x11250000 0x15 0xffff0000>;
			msdc3_base = <0x11260000 0x16 0xffff0000>;
			pwm_sw_base = <0x1100e000 0x63 0xfffff000>;
			reg = <0x10217000 0x1000>;
			scp_base = <0x10050000 0xd 0xffff0000>;
			scp_sram_base = <0x10020000 0xa 0xffff0000>;
			seninf_cam0_fifo_full = <0x49>;
			seninf_cam1_2_3_fifo_full = <0x48>;
			stream_done_0 = <0x23>;
			stream_done_1 = <0x24>;
			stream_done_2 = <0x25>;
			stream_done_3 = <0x26>;
			stream_done_4 = <0x27>;
			stream_done_5 = <0x28>;
			stream_done_6 = <0x29>;
			stream_done_7 = <0x2a>;
			stream_done_8 = <0x2b>;
			stream_done_9 = <0x2c>;
			topckgen_base = <0x10000000 0x8 0xffff0000>;
			usb0_base = <0x11200000 0x10 0xffff0000>;
			usb_sif_base = <0x11210000 0x11 0xffff0000>;
			vdec_gcon_base = <0x16000000 0x5 0xffff0000>;
			venc_128byte_cnt_done = <0x85>;
			venc_done = <0x81>;
			venc_gcon_base = <0x17000000 0x6 0xffff0000>;
			venc_mb_done = <0x84>;
		};

		gcpu@10216000 {
			compatible = "mediatek,gcpu";
			interrupts = <0x0 0x96 0x8>;
			reg = <0x10216000 0x1000>;
		};

		gpio {
			GPIO_SIM1_HOT_PLUG = <0x8>;
			GPIO_SIM1_SCLK = <0xa3>;
			GPIO_SIM1_SIO = <0xa5>;
			GPIO_SIM1_SRST = <0xa4>;
			GPIO_SIM2_SCLK = <0xa0>;
			GPIO_SIM2_SIO = <0xa2>;
			GPIO_SIM2_SRST = <0xa1>;
			compatible = "mediatek,gpio_usage_mapping";
		};

		gpio@10211000 {
			compatible = "mediatek,gpio";
			reg = <0x10211000 0x1000>;
		};

		gps {
			compatible = "mediatek,mt3326-gps";
		};

		hacc@10008000 {
			compatible = "mediatek,hacc";
			interrupts = <0x0 0xae 0x8>;
			reg = <0x10008000 0x1000>;
		};

		hall_1 {
			compatible = "mediatek,hall";
			debounce = <0x7 0x0>;
			interrupt-parent = <0xc>;
			interrupts = <0x7 0x1>;
			pinctrl-0 = <0x70>;
			pinctrl-1 = <0x71>;
			pinctrl-names = "default", "hall_pins_as_eint";
			status = "okay";
		};

		i2c@11007000 {
			#address-cells = <0x1>;
			#size-cells = <0x0>;
			cell-index = <0x0>;
			clock-div = <0x1>;
			clock-frequency = <0x3520>;
			clock-names = "i2c0-main", "i2c0-dma";
			clocks = <0x2 0x18 0x2 0xd>;
			compatible = "mediatek,mt6735-i2c";
			def_speed = <0x64>;
			interrupts = <0x0 0x54 0x8 0x0 0x63 0x8>;
			reg = <0x11007000 0x1000>;

			camera_main@10 {
				compatible = "mediatek,camera_main";
				reg = <0x10>;
				status = "okay";
			};

			camera_main_af@0c {
				compatible = "mediatek,camera_main_af";
				reg = <0xc>;
				status = "okay";
			};
		};

		i2c@11008000 {
			#address-cells = <0x1>;
			#size-cells = <0x0>;
			cell-index = <0x1>;
			clock-div = <0x1>;
			clock-frequency = <0x3520>;
			clock-names = "i2c1-main", "i2c1-dma";
			clocks = <0x2 0x19 0x2 0xd>;
			compatible = "mediatek,mt6735-i2c";
			def_speed = <0x64>;
			interrupts = <0x0 0x55 0x8 0x0 0x64 0x8>;
			reg = <0x11008000 0x1000>;

			cap_touch@5d {
				compatible = "mediatek,cap_touch";
				reg = <0x5d>;
				status = "okay";
			};

			i2c_lcd_bias@3e {
				compatible = "mediatek,i2c_lcd_bias";
				reg = <0x3e>;
				status = "okay";
			};

			swithing_charger@36 {
				compatible = "mediatek,swithing_charger";
				reg = <0x36>;
				status = "okay";
			};
		};

		i2c@11009000 {
			#address-cells = <0x1>;
			#size-cells = <0x0>;
			cell-index = <0x2>;
			clock-div = <0x1>;
			clock-frequency = <0x3520>;
			clock-names = "i2c2-main", "i2c2-dma";
			clocks = <0x2 0x1a 0x2 0xd>;
			compatible = "mediatek,mt6735-i2c";
			def_speed = <0x64>;
			interrupts = <0x0 0x56 0x8 0x0 0x65 0x8>;
			reg = <0x11009000 0x1000>;

			alsps@48 {
				compatible = "mediatek,alsps";
				reg = <0x48>;
				status = "okay";
			};

			camera_sub@3c {
				compatible = "mediatek,camera_sub";
				reg = <0x3c>;
				status = "okay";
			};

			gsensor@4c {
				compatible = "mediatek,gsensor";
				reg = <0x4c>;
				status = "okay";
			};

			gyro@68 {
				compatible = "mediatek,gyro";
				reg = <0x68>;
				status = "okay";
			};

			msensor@0d {
				compatible = "mediatek,msensor";
				reg = <0xd>;
				status = "okay";
			};

			nfc@28 {
				compatible = "mediatek,nfc";
				reg = <0x28>;
				status = "okay";
			};

			strobe_main@63 {
				compatible = "mediatek,strobe_main";
				reg = <0x63>;
				status = "okay";
			};
		};

		i2c@1100f000 {
			#address-cells = <0x1>;
			#size-cells = <0x0>;
			cell-index = <0x3>;
			clock-div = <0x1>;
			clock-frequency = <0x3520>;
			clock-names = "i2c3-main", "i2c3-dma";
			clocks = <0x2 0x1b 0x2 0xd>;
			compatible = "mediatek,mt6735-i2c";
			def_speed = <0x64>;
			interrupts = <0x0 0x57 0x8 0x0 0x66 0x8>;
			reg = <0x1100f000 0x1000>;

			ext_buck@6b {
				compatible = "mediatek,ext_buck";
				reg = <0x6b>;
				status = "okay";
			};
		};

		imgsys@15000000 {
			#clock-cells = <0x1>;
			compatible = "mediatek,mt6735-imgsys";
			linux,phandle = <0x1a>;
			phandle = <0x1a>;
			reg = <0x15000000 0x1000>;
		};

		infracfg_ao@10000000 {
			compatible = "mediatek,infracfg_ao";
			reg = <0x10000000 0x1000>;
		};

		infrasys@10000000 {
			#clock-cells = <0x1>;
			compatible = "mediatek,mt6735-infrasys";
			linux,phandle = <0x17>;
			phandle = <0x17>;
			reg = <0x10000000 0x1000>;
		};

		irlearning-spi {
			compatible = "mediatek,irlearning-spi";
			spi_clock = <0x67f3540>;
			spi_cs_invert = <0x1>;
			spi_data_invert = <0x0>;
		};

		irtx-pwm {
			compatible = "mediatek,irtx-pwm";
			pwm_ch = <0x2>;
			pwm_data_invert = <0x0>;
		};

		irtx@11011000 {
			clock-div = <0x1>;
			clock-frequency = <0x18cba80>;
			clock-names = "clk-irtx-main";
			clocks = <0x2 0x1e>;
			compatible = "mediatek,irtx";
			interrupts = <0x0 0x7c 0x4>;
			pinctrl-0 = <0x1d>;
			pinctrl-1 = <0x1e>;
			pinctrl-names = "irtx_gpio_default", "irtx_gpio_led_set";
			pwm_ch = <0x0>;
			reg = <0x11011000 0x1000>;
			status = "okay";
		};

		ispsys@15000000 {
			clock-names = "CG_SCP_SYS_DIS", "CG_SCP_SYS_ISP", "CG_DISP0_SMI_COMMON", "CG_IMAGE_CAM_SMI", "CG_IMAGE_CAM_CAM", "CG_IMAGE_SEN_TG", "CG_IMAGE_SEN_CAM", "CG_IMAGE_CAM_SV", "CG_IMAGE_LARB2_SMI";
			clocks = <0x11 0x4 0x11 0x6 0x18 0x1 0x1a 0x2 0x1a 0x3 0x1a 0x4 0x1a 0x5 0x1a 0x6 0x1a 0x1>;
			compatible = "mediatek,mt6735-ispsys";
			interrupts = <0x0 0xb7 0x8 0x0 0xb8 0x8 0x0 0xb9 0x8 0x0 0xce 0x8 0x0 0xcf 0x8>;
			reg = <0x15004000 0x9000 0x1500d000 0x1000 0x15000000 0x10000 0x10215000 0x3000 0x10211000 0x1000>;
		};

		jpgdec@17004000 {
			clock-names = "disp-mtcmos", "disp-smi", "venc-mtcmos", "venc-larb", "venc-jpgdec";
			clocks = <0x11 0x4 0x18 0x1 0x11 0x8 0x1b 0x1 0x1b 0x4>;
			compatible = "mediatek,jpgdec";
			interrupts = <0x0 0xd1 0x8>;
			reg = <0x17004000 0x1000>;
		};

		jpgenc@17003000 {
			clock-names = "disp-mtcmos", "disp-smi", "venc-mtcmos", "venc-larb", "venc-jpgenc";
			clocks = <0x11 0x4 0x18 0x1 0x11 0x8 0x1b 0x1 0x1b 0x3>;
			compatible = "mediatek,jpgenc";
			interrupts = <0x0 0xb5 0x8>;
			reg = <0x17003000 0x1000>;
		};

		kd_camera_hw1@15008000 {
			clock-names = "TOP_CAMTG_SEL", "TOP_UNIVPLL_D26", "TOP_UNIVPLL2_D2";
			clocks = <0x3 0x8 0x3 0x3f 0x3 0x44>;
			compatible = "mediatek,camera_hw";
			pinctrl-0 = <0x41>;
			pinctrl-1 = <0x42>;
			pinctrl-10 = <0x4b>;
			pinctrl-11 = <0x4c>;
			pinctrl-12 = <0x4d>;
			pinctrl-13 = <0x4e>;
			pinctrl-14 = <0x4f>;
			pinctrl-15 = <0x50>;
			pinctrl-16 = <0x51>;
			pinctrl-17 = <0x52>;
			pinctrl-18 = <0x53>;
			pinctrl-2 = <0x43>;
			pinctrl-3 = <0x44>;
			pinctrl-4 = <0x45>;
			pinctrl-5 = <0x46>;
			pinctrl-6 = <0x47>;
			pinctrl-7 = <0x48>;
			pinctrl-8 = <0x49>;
			pinctrl-9 = <0x4a>;
			pinctrl-names = "default", "cam0_rst0", "cam0_rst1", "cam0_pnd0", "cam0_pnd1", "cam1_rst0", "cam1_rst1", "cam1_pnd0", "cam1_pnd1", "lens_af_en_0", "lens_af_en_1", "flash_mode_0", "flash_mode_1", "flash_en_0", "flash_en_1", "cam_ldo_avdd_0", "cam_ldo_avdd_1", "cam_ldo_dvdd_0", "cam_ldo_dvdd_1";
			reg = <0x15008000 0x1000>;
			status = "okay";
			vcama-supply = <0x3d>;
			vcama_main2-supply = <0x3d>;
			vcama_sub-supply = <0x3d>;
			vcamaf-supply = <0x3f>;
			vcamaf_main2-supply = <0x3f>;
			vcamaf_sub-supply = <0x3f>;
			vcamd-supply = <0x3e>;
			vcamd_main2-supply = <0x3e>;
			vcamd_sub-supply = <0x3e>;
			vcamio-supply = <0x40>;
			vcamio_main2-supply = <0x40>;
			vcamio_sub-supply = <0x40>;
		};

		kd_camera_hw2@15008000 {
			compatible = "mediatek,camera_hw2";
			reg = <0x15008000 0x1000>;
		};

		keypad@10003000 {
			compatible = "mediatek,mt6735-keypad";
			interrupts = <0x0 0xa4 0x2>;
			mediatek,kpd-hw-dl-key0 = <0x11>;
			mediatek,kpd-hw-dl-key1 = <0x0>;
			mediatek,kpd-hw-dl-key2 = <0x8>;
			mediatek,kpd-hw-factory-key = <0x0>;
			mediatek,kpd-hw-init-map = <0x72 0x0 0x0 0x0 0x0 0x0 0x0 0x0 0x0 0x0 0x0 0x0 0x0 0x0 0x0 0x0 0x0 0x0 0x0 0x0 0x0 0x0 0x0 0x0 0x0 0x0 0x0 0x0 0x0 0x0 0x0 0x0 0x0 0x0 0x0 0x0 0x0 0x0 0x0 0x0 0x0 0x0 0x0 0x0 0x0 0x0 0x0 0x0 0x0 0x0 0x0 0x0 0x0 0x0 0x0 0x0 0x0 0x0 0x0 0x0 0x0 0x0 0x0 0x0 0x0 0x0 0x0 0x0 0x0 0x0 0x0 0x0>;
			mediatek,kpd-hw-map-num = <0x48>;
			mediatek,kpd-hw-pwrkey = <0x8>;
			mediatek,kpd-hw-recovery-key = <0x11>;
			mediatek,kpd-hw-rstkey = <0x11>;
			mediatek,kpd-key-debounce = <0x400>;
			mediatek,kpd-pwkey-gpio-din = <0x0>;
			mediatek,kpd-pwrkey-eint-gpio = <0x0>;
			mediatek,kpd-sw-pwrkey = <0x74>;
			mediatek,kpd-sw-rstkey = <0x73>;
			mediatek,kpd-use-extend-type = <0x0>;
			reg = <0x10003000 0x1000>;
			status = "okay";
		};

		lastpc@10200000 {
			compatible = "mediatek,mt6735-mcucfg";
			interrupts = <0x0 0x47 0x4>;
			reg = <0x10200000 0x200>;
		};

		lcm_mode {
			compatible = "mediatek,lcm_mode";
		};

		ledrgb {
			compatible = "mediatek,mt6735-led-rgb";
			pinctrl-0 = <0x65>;
			pinctrl-1 = <0x66>;
			pinctrl-2 = <0x67>;
			pinctrl-3 = <0x68>;
			pinctrl-4 = <0x69>;
			pinctrl-5 = <0x6a>;
			pinctrl-6 = <0x6b>;
			pinctrl-names = "default", "led_rgb_red_0", "led_rgb_red_1", "led_rgb_green_0", "led_rgb_green_1", "led_rgb_blue_0", "led_rgb_blue_1";
			status = "okay";
		};

		m4u@10205000 {
			cell-index = <0x0>;
			clock-names = "infra_m4u", "smi_common", "m4u_disp0_smi_larb0", "m4u_vdec0_vdec", "m4u_vdec1_larb", "m4u_img_image_larb2_smi", "m4u_venc_venc", "m4u_venc_larb";
			clocks = <0x17 0x9 0x18 0x1 0x18 0x2 0x19 0x1 0x19 0x2 0x1a 0x1 0x1b 0x2 0x1b 0x1>;
			compatible = "mediatek,m4u";
			interrupts = <0x0 0x92 0x8>;
			reg = <0x10205000 0x1000>;
		};

		mali@13040000 {
			clock-frequency = <0x1ad27480>;
			clock-names = "mfg-main", "mfg-smi-common", "mtcmos-mfg", "mtcmos-display";
			clocks = <0x3c 0x1 0x18 0x1 0x11 0x5 0x11 0x4>;
			compatible = "arm,malit720", "arm,mali-t72x", "arm,malit7xx", "arm,mali-midgard";
			interrupt-names = "JOB", "MMU", "GPU";
			interrupts = <0x0 0xd4 0x8 0x0 0xd3 0x8 0x0 0xd2 0x8>;
			reg = <0x13040000 0x4000>;
		};

		mcu_biu@10300000 {
			compatible = "mediatek,mt6735-mcu_biu";
			reg = <0x10300000 0x8000>;
		};

		mcucfg@10200000 {
			compatible = "mediatek,mcucfg";
			interrupts = <0x0 0x47 0x4>;
			reg = <0x10200000 0x200>;
		};

		mdc2k@3a00b01c {
			clock-names = "scp-sys-md2-main";
			clocks = <0x11 0x2>;
			compatible = "mediatek,mdc2k";
			interrupts = <0x0 0xe5 0x2>;
			reg = <0x3a00b01c 0x10 0x1021c800 0x300 0x1021d800 0x300>;
		};

		mdcldma@1000A000 {
			clock-names = "scp-sys-md1-main";
			clocks = <0x11 0x1>;
			compatible = "mediatek,mdcldma";
			interrupts = <0x0 0x91 0x4 0x0 0x8c 0x8 0x0 0xdd 0x2>;
			mediatek,cldma_capability = <0x6>;
			mediatek,md_id = <0x0>;
			mediatek,md_smem_size = <0x10000>;
			pinctrl-0 = <0x12>;
			pinctrl-1 = <0x13>;
			pinctrl-2 = <0x14>;
			pinctrl-3 = <0x15>;
			pinctrl-4 = <0x16>;
			pinctrl-names = "default", "vsram_output_low", "vsram_output_high", "RFIC0_01_mode", "RFIC0_04_mode";
			reg = <0x1000a000 0x1000 0x1000b000 0x1000 0x1021a000 0x1000 0x1021b000 0x1000 0x1020a000 0x1000 0x1020b000 0x1000>;
		};

		mdp_rdma@14001000 {
			clock-names = "MDP_RDMA";
			clocks = <0x18 0x4>;
			compatible = "mediatek,mdp_rdma";
			interrupts = <0x0 0xbb 0x8>;
			reg = <0x14001000 0x1000>;
		};

		mdp_rsz0@14002000 {
			clock-names = "MDP_RSZ0";
			clocks = <0x18 0x5>;
			compatible = "mediatek,mdp_rsz0";
			interrupts = <0x0 0xbc 0x8>;
			reg = <0x14002000 0x1000>;
		};

		mdp_rsz1@14003000 {
			clock-names = "MDP_RSZ1";
			clocks = <0x18 0x6>;
			compatible = "mediatek,mdp_rsz1";
			interrupts = <0x0 0xbd 0x8>;
			reg = <0x14003000 0x1000>;
		};

		mdp_tdshp@14006000 {
			clock-names = "MDP_TDSHP";
			clocks = <0x18 0x7>;
			compatible = "mediatek,mdp_tdshp";
			interrupts = <0x0 0xbe 0x8>;
			reg = <0x14006000 0x1000>;
		};

		mdp_wdma@14004000 {
			clock-names = "MDP_WDMA";
			clocks = <0x18 0x8>;
			compatible = "mediatek,mdp_wdma";
			interrupts = <0x0 0xbf 0x8>;
			reg = <0x14004000 0x1000>;
		};

		mdp_wrot@14005000 {
			clock-names = "MDP_WROT";
			clocks = <0x18 0x9>;
			compatible = "mediatek,mdp_wrot";
			interrupts = <0x0 0xc0 0x8>;
			reg = <0x14005000 0x1000>;
		};

		met_smi@14016000 {
			clock-names = "smi-common", "smi-larb0", "img-larb2", "vdec0-vdec", "vdec1-larb", "venc-larb", "venc-venc";
			clocks = <0x18 0x1 0x18 0x2 0x1a 0x1 0x19 0x1 0x19 0x2 0x1b 0x1 0x1b 0x2>;
			compatible = "mediatek,met_smi";
			reg = <0x14016000 0x1000 0x14015000 0x1000 0x16010000 0x1000 0x15001000 0x1000 0x17001000 0x1000>;
		};

		mfgsys@13000000 {
			#clock-cells = <0x1>;
			compatible = "mediatek,mt6735-mfgsys";
			linux,phandle = <0x3c>;
			phandle = <0x3c>;
			reg = <0x13000000 0x1000>;
		};

		mmsys@14000000 {
			#clock-cells = <0x1>;
			compatible = "mediatek,mt6735-mmsys";
			linux,phandle = <0x18>;
			phandle = <0x18>;
			reg = <0x14000000 0x1000>;
		};

		mmsys_config@14000000 {
			clock-names = "CAM_MDP";
			clocks = <0x18 0x3>;
			compatible = "mediatek,mmsys_config";
			interrupts = <0x0 0xcd 0x8>;
			reg = <0x14000000 0x1000>;
		};

		mt_pmic_regulator {
			compatible = "mediatek,mt_pmic";

			buck_regulators {
				compatible = "mediatek,mt_pmic_buck_regulators";

				buck_vcore1 {
					regulator-always-on;
					regulator-boot-on;
					regulator-enable-ramp-delay = <0xb4>;
					regulator-max-microvolt = <0x154456>;
					regulator-min-microvolt = <0x927c0>;
					regulator-name = "vcore1";
					regulator-ramp-delay = <0x186a>;
				};

				buck_vlte {
					regulator-always-on;
					regulator-boot-on;
					regulator-enable-ramp-delay = <0xb4>;
					regulator-max-microvolt = <0x154456>;
					regulator-min-microvolt = <0x927c0>;
					regulator-name = "vlte";
					regulator-ramp-delay = <0x186a>;
				};

				buck_vpa {
					regulator-enable-ramp-delay = <0xb4>;
					regulator-max-microvolt = <0x37b1d0>;
					regulator-min-microvolt = <0x7a120>;
					regulator-name = "vpa";
					regulator-ramp-delay = <0xc350>;
				};

				buck_vproc {
					regulator-always-on;
					regulator-boot-on;
					regulator-enable-ramp-delay = <0xb4>;
					regulator-max-microvolt = <0x154456>;
					regulator-min-microvolt = <0x927c0>;
					regulator-name = "vproc";
					regulator-ramp-delay = <0x186a>;
				};

				buck_vsys22 {
					regulator-always-on;
					regulator-boot-on;
					regulator-enable-ramp-delay = <0xb4>;
					regulator-max-microvolt = <0x1e6c16>;
					regulator-min-microvolt = <0x124f80>;
					regulator-name = "vsys22";
					regulator-ramp-delay = <0x186a>;
				};
			};

			ldo_regulators {
				compatible = "mediatek,mt_pmic_ldo_regulators";

				ldo_vaud28 {
					linux,phandle = <0x81>;
					phandle = <0x81>;
					regulator-boot-on;
					regulator-enable-ramp-delay = <0x108>;
					regulator-max-microvolt = <0x2ab980>;
					regulator-min-microvolt = <0x2ab980>;
					regulator-name = "vaud28";
				};

				ldo_vaux18 {
					linux,phandle = <0x7e>;
					phandle = <0x7e>;
					regulator-boot-on;
					regulator-enable-ramp-delay = <0x108>;
					regulator-max-microvolt = <0x1b7740>;
					regulator-min-microvolt = <0x1b7740>;
					regulator-name = "vaux18";
				};

				ldo_vcama {
					linux,phandle = <0x3d>;
					phandle = <0x3d>;
					regulator-default-on = <0x0>;
					regulator-enable-ramp-delay = <0x108>;
					regulator-max-microvolt = <0x2ab980>;
					regulator-min-microvolt = <0x16e360>;
					regulator-name = "vcama";
					status = "okay";
				};

				ldo_vcamaf {
					linux,phandle = <0x3f>;
					phandle = <0x3f>;
					regulator-default-on = <0x0>;
					regulator-enable-ramp-delay = <0x108>;
					regulator-max-microvolt = <0x325aa0>;
					regulator-min-microvolt = <0x124f80>;
					regulator-name = "vcamaf";
					status = "okay";
				};

				ldo_vcamd {
					linux,phandle = <0x3e>;
					phandle = <0x3e>;
					regulator-default-on = <0x0>;
					regulator-enable-ramp-delay = <0x108>;
					regulator-max-microvolt = <0x16e360>;
					regulator-min-microvolt = <0xdbba0>;
					regulator-name = "vcamd";
					status = "okay";
				};

				ldo_vcamio {
					linux,phandle = <0x40>;
					phandle = <0x40>;
					regulator-default-on = <0x0>;
					regulator-enable-ramp-delay = <0xdc>;
					regulator-max-microvolt = <0x1b7740>;
					regulator-min-microvolt = <0x124f80>;
					regulator-name = "vcamio";
					status = "okay";
				};

				ldo_vcn18 {
					linux,phandle = <0x54>;
					phandle = <0x54>;
					regulator-enable-ramp-delay = <0x2c>;
					regulator-max-microvolt = <0x1b7740>;
					regulator-min-microvolt = <0x1b7740>;
					regulator-name = "vcn18";
				};

				ldo_vcn28 {
					linux,phandle = <0x55>;
					phandle = <0x55>;
					regulator-enable-ramp-delay = <0x108>;
					regulator-max-microvolt = <0x2ab980>;
					regulator-min-microvolt = <0x2ab980>;
					regulator-name = "vcn28";
				};

				ldo_vcn33_bt {
					linux,phandle = <0x56>;
					phandle = <0x56>;
					regulator-enable-ramp-delay = <0x108>;
					regulator-max-microvolt = <0x36ee80>;
					regulator-min-microvolt = <0x325aa0>;
					regulator-name = "vcn33_bt";
				};

				ldo_vcn33_wifi {
					linux,phandle = <0x57>;
					phandle = <0x57>;
					regulator-enable-ramp-delay = <0x108>;
					regulator-max-microvolt = <0x36ee80>;
					regulator-min-microvolt = <0x325aa0>;
					regulator-name = "vcn33_wifi";
				};

				ldo_vefuse {
					linux,phandle = <0x82>;
					phandle = <0x82>;
					regulator-enable-ramp-delay = <0x108>;
					regulator-max-microvolt = <0x2191c0>;
					regulator-min-microvolt = <0x1b7740>;
					regulator-name = "vefuse";
				};

				ldo_vemc_3v3 {
					linux,phandle = <0x85>;
					phandle = <0x85>;
					regulator-boot-on;
					regulator-enable-ramp-delay = <0x108>;
					regulator-max-microvolt = <0x325aa0>;
					regulator-min-microvolt = <0x1b7740>;
					regulator-name = "vemc_3v3";
				};

				ldo_vgp1 {
					linux,phandle = <0x5c>;
					phandle = <0x5c>;
					regulator-default-on = <0x0>;
					regulator-enable-ramp-delay = <0x108>;
					regulator-max-microvolt = <0x325aa0>;
					regulator-min-microvolt = <0x124f80>;
					regulator-name = "vgp1";
					status = "okay";
				};

				ldo_vibr {
					linux,phandle = <0x8a>;
					phandle = <0x8a>;
					regulator-default-on = <0x0>;
					regulator-enable-ramp-delay = <0x2c>;
					regulator-max-microvolt = <0x325aa0>;
					regulator-min-microvolt = <0x124f80>;
					regulator-name = "vibr";
					status = "okay";
				};

				ldo_vio18 {
					linux,phandle = <0x8d>;
					phandle = <0x8d>;
					regulator-boot-on;
					regulator-enable-ramp-delay = <0x108>;
					regulator-max-microvolt = <0x1b7740>;
					regulator-min-microvolt = <0x1b7740>;
					regulator-name = "vio18";
				};

				ldo_vio28 {
					linux,phandle = <0x89>;
					phandle = <0x89>;
					regulator-boot-on;
					regulator-enable-ramp-delay = <0x108>;
					regulator-max-microvolt = <0x2ab980>;
					regulator-min-microvolt = <0x2ab980>;
					regulator-name = "vio28";
				};

				ldo_vm {
					linux,phandle = <0x8f>;
					phandle = <0x8f>;
					regulator-boot-on;
					regulator-enable-ramp-delay = <0x108>;
					regulator-max-microvolt = <0x177fa0>;
					regulator-min-microvolt = <0x12ebc0>;
					regulator-name = "vm";
				};

				ldo_vmc {
					linux,phandle = <0x88>;
					phandle = <0x88>;
					regulator-boot-on;
					regulator-enable-ramp-delay = <0x2c>;
					regulator-max-microvolt = <0x325aa0>;
					regulator-min-microvolt = <0x1b7740>;
					regulator-name = "vmc";
				};

				ldo_vmch {
					linux,phandle = <0x86>;
					phandle = <0x86>;
					regulator-enable-ramp-delay = <0x2c>;
					regulator-max-microvolt = <0x325aa0>;
					regulator-min-microvolt = <0x2c4020>;
					regulator-name = "vmch";
				};

				ldo_vrf18_0 {
					linux,phandle = <0x8b>;
					phandle = <0x8b>;
					regulator-enable-ramp-delay = <0xdc>;
					regulator-max-microvolt = <0x1bd8e8>;
					regulator-min-microvolt = <0x1bd8e8>;
					regulator-name = "vrf18_0";
				};

				ldo_vrf18_1 {
					linux,phandle = <0x8c>;
					phandle = <0x8c>;
					regulator-enable-ramp-delay = <0xdc>;
					regulator-max-microvolt = <0x1bd8e8>;
					regulator-min-microvolt = <0x124f80>;
					regulator-name = "vrf18_1";
				};

				ldo_vsim1 {
					linux,phandle = <0x83>;
					phandle = <0x83>;
					regulator-default-on = <0x0>;
					regulator-enable-ramp-delay = <0x108>;
					regulator-max-microvolt = <0x200b20>;
					regulator-min-microvolt = <0x19f0a0>;
					regulator-name = "vsim1";
					status = "okay";
				};

				ldo_vsim2 {
					linux,phandle = <0x84>;
					phandle = <0x84>;
					regulator-default-on = <0x0>;
					regulator-enable-ramp-delay = <0x108>;
					regulator-max-microvolt = <0x200b20>;
					regulator-min-microvolt = <0x19f0a0>;
					regulator-name = "vsim2";
					status = "okay";
				};

				ldo_vsram {
					linux,phandle = <0x8e>;
					phandle = <0x8e>;
					regulator-boot-on;
					regulator-enable-ramp-delay = <0xdc>;
					regulator-max-microvolt = <0x16caf6>;
					regulator-min-microvolt = <0xaae60>;
					regulator-name = "vsram";
					regulator-ramp-delay = <0x186a>;
				};

				ldo_vtcxo_0 {
					linux,phandle = <0x7f>;
					phandle = <0x7f>;
					regulator-boot-on;
					regulator-enable-ramp-delay = <0x6e>;
					regulator-max-microvolt = <0x2ab980>;
					regulator-min-microvolt = <0x2ab980>;
					regulator-name = "vtcxo_0";
				};

				ldo_vtcxo_1 {
					linux,phandle = <0x80>;
					phandle = <0x80>;
					regulator-enable-ramp-delay = <0x6e>;
					regulator-max-microvolt = <0x2ab980>;
					regulator-min-microvolt = <0x2ab980>;
					regulator-name = "vtcxo_1";
				};

				ldo_vtref {
					linux,phandle = <0x87>;
					phandle = <0x87>;
					regulator-enable-ramp-delay = <0xf0>;
					regulator-max-microvolt = <0x1b7740>;
					regulator-min-microvolt = <0x1b7740>;
					regulator-name = "vtref";
				};

				ldo_vusb33 {
					linux,phandle = <0x33>;
					phandle = <0x33>;
					regulator-boot-on;
					regulator-enable-ramp-delay = <0x108>;
					regulator-max-microvolt = <0x325aa0>;
					regulator-min-microvolt = <0x325aa0>;
					regulator-name = "vusb33";
				};
			};

			regulators_supply {
				compatible = "mediatek,mt_pmic_regulator_supply";
				vaud28-supply = <0x81>;
				vaux18-supply = <0x7e>;
				vefuse-supply = <0x82>;
				vemc_3v3-supply = <0x85>;
				vibr-supply = <0x8a>;
				vio18-supply = <0x8d>;
				vio28-supply = <0x89>;
				vm-supply = <0x8f>;
				vmc-supply = <0x88>;
				vmch-supply = <0x86>;
				vrf18_0-supply = <0x8b>;
				vrf18_1-supply = <0x8c>;
				vsim1-supply = <0x83>;
				vsim2-supply = <0x84>;
				vsram-supply = <0x8e>;
				vtcxo_0-supply = <0x7f>;
				vtcxo_1-supply = <0x80>;
				vtref-supply = <0x87>;
			};
		};

		mt_soc_codec_dummy_name {
			compatible = "mediatek,mt_soc_codec_dummy";
		};

		mt_soc_codec_name {
			compatible = "mediatek,mt_soc_codec_63xx";
		};

		mt_soc_dai_name {
			compatible = "mediatek,mt_soc_dai_stub";
		};

		mt_soc_dl1_awb_pcm {
			compatible = "mediatek,mt_soc_pcm_dl1_awb";
		};

		mt_soc_dl1_pcm@11220000 {
			audclk-gpio = <0x8f 0x0>;
			audmiso-gpio = <0x90 0x0>;
			audmosi-gpio = <0x91 0x0>;
			clock-names = "aud_afe_clk", "aud_i2s_clk", "aud_dac_clk", "aud_dac_predis_clk", "aud_adc_clk", "aud_apll22m_clk", "aud_apll24m_clk", "aud_apll1_tuner_clk", "aud_apll2_tuner_clk", "aud_tml_clk", "aud_infra_clk", "aud_mux1_clk", "aud_mux2_clk", "top_ad_apll1_clk", "top_whpll_audio_clk", "top_mux_audio", "top_mux_audio_int", "top_sys_pll1_d4", "apmixed_apll1_clk", "apmixed_apll2_clk", "top_clk26m_clk";
			clocks = <0x39 0x1 0x39 0x2 0x39 0x8 0x39 0x9 0x39 0x7 0x39 0x3 0x39 0x4 0x39 0x6 0x39 0x5 0x39 0xa 0x17 0x6 0x3 0x19 0x3 0x1a 0x3 0x21 0x3 0x4b 0x3 0x11 0x3 0x12 0x3 0x33 0x3a 0x8 0x3a 0x9 0x3b>;
			compatible = "mediatek,mt-soc-dl1-pcm";
			extspkamp-gpio = <0x75 0x0>;
			i2s1clk-gpio = <0x50 0x0>;
			i2s1dat-gpio = <0x4e 0x0>;
			i2s1mclk-gpio = <0x9 0x0>;
			i2s1ws-gpio = <0x4f 0x0>;
			interrupts = <0x0 0x90 0x8>;
			reg = <0x11220000 0x1000>;
			vowclk-gpio = <0x94 0x0>;
		};

		mt_soc_dl2_pcm {
			compatible = "mediatek,mt_soc_pcm_dl2";
		};

		mt_soc_dummy_pcm {
			compatible = "mediatek,mt_soc_pcm_dummy";
		};

		mt_soc_fm_i2s_awb_pcm {
			compatible = "mediatek,mt_soc_pcm_fm_i2s_awb";
		};

		mt_soc_fm_i2s_pcm {
			compatible = "mediatek,mt_soc_pcm_fm_i2s";
		};

		mt_soc_fm_mrgtx_pcm {
			compatible = "mediatek,mt_soc_pcm_fmtx";
		};

		mt_soc_hdmi_pcm {
			compatible = "mediatek,mt_soc_pcm_hdmi";
		};

		mt_soc_hp_impedance_pcm {
			compatible = "mediatek,Mt_soc_pcm_hp_impedance";
		};

		mt_soc_i2s0_awb_pcm {
			compatible = "mediatek,mt_soc_pcm_i2s0_awb";
		};

		mt_soc_i2s0_pcm {
			compatible = "mediatek,mt_soc_pcm_dl1_i2s0";
		};

		mt_soc_i2s0dl1_pcm {
			compatible = "mediatek,mt_soc_pcm_dl1_i2s0Dl1";
		};

		mt_soc_mrgrx_awb_pcm {
			compatible = "mediatek,mt_soc_pcm_mrgrx_awb";
		};

		mt_soc_mrgrx_pcm {
			compatible = "mediatek,mt_soc_pcm_mrgrx";
		};

		mt_soc_offload_gdma {
			compatible = "mediatek,mt_soc_pcm_offload_gdma";
		};

		mt_soc_routing_dai_name {
			compatible = "mediatek,mt_soc_dai_routing";
		};

		mt_soc_routing_pcm {
			compatible = "mediatek,mt_soc_pcm_routing";
			i2s1clk-gpio = <0x7 0x6>;
			i2s1dat-gpio = <0x5 0x6>;
			i2s1mclk-gpio = <0x9 0x6>;
			i2s1ws-gpio = <0x6 0x6>;
		};

		mt_soc_tdmrx_pcm {
			compatible = "mediatek,mt_soc_tdm_capture";
		};

		mt_soc_ul1_pcm {
			compatible = "mediatek,mt_soc_pcm_capture";
		};

		mt_soc_ul2_pcm {
			compatible = "mediatek,mt_soc_pcm_capture2";
		};

		mt_soc_uldlloopback_pcm {
			compatible = "mediatek,mt_soc_pcm_uldlloopback";
		};

		mt_soc_voice_md1 {
			compatible = "mediatek,mt_soc_pcm_voice_md1";
		};

		mt_soc_voice_md1_bt {
			compatible = "mediatek,mt_soc_pcm_voice_md1_bt";
		};

		mt_soc_voice_md2 {
			compatible = "mediatek,mt_soc_pcm_voice_md2";
		};

		mt_soc_voice_md2_bt {
			compatible = "mediatek,mt_soc_pcm_voice_md2_bt";
		};

		mt_soc_voip_bt_in {
			compatible = "mediatek,mt_soc_pcm_bt_dai";
		};

		mt_soc_voip_bt_out {
			compatible = "mediatek,mt_soc_pcm_dl1_bt";
		};

		mtkfb@7f000000 {
			compatible = "mediatek,mtkfb";
			reg = <0x7f000000 0x1000000>;
		};

		nfc {
			compatible = "mediatek,nfc-gpio-v2";
			gpio-eint = <0x1>;
			gpio-irq = <0x2>;
			gpio-rst = <0x3>;
			gpio-ven = <0x4>;
			pinctrl-0 = <0x58>;
			pinctrl-1 = <0x72>;
			pinctrl-2 = <0x73>;
			pinctrl-3 = <0x74>;
			pinctrl-4 = <0x75>;
			pinctrl-5 = <0x76>;
			pinctrl-6 = <0x77>;
			pinctrl-7 = <0x78>;
			pinctrl-names = "default", "ven_high", "ven_low", "rst_high", "rst_low", "eint_high", "eint_low", "irq_init";
			status = "okay";
		};

		pericfg@10002000 {
			compatible = "mediatek,pericfg";
			reg = <0x10002000 0x1000>;
		};

		perisys@10002000 {
			#clock-cells = <0x1>;
			compatible = "mediatek,mt6735-perisys";
			linux,phandle = <0x2>;
			phandle = <0x2>;
			reg = <0x10002000 0x1000>;
		};

		pinctrl@10211000 {
			#gpio-cells = <0x2>;
			compatible = "mediatek,mt6735-pinctrl";
			gpio-controller;
			linux,phandle = <0xb>;
			mediatek,pctl-regmap = <0x1c>;
			phandle = <0xb>;
			pins-are-numbered;
			reg = <0x0 0x9bceb8 0x0 0x3e8>;

			alspsdefaultcfg {
				linux,phandle = <0x90>;
				phandle = <0x90>;
			};

			alspspincfg {
				linux,phandle = <0x91>;
				phandle = <0x91>;

				pins_cmd_dat {
					bias-pull-up = <0x0>;
					pins = <0x300>;
					slew-rate = <0x0>;
				};
			};

			cam0@0 {
				linux,phandle = <0x42>;
				phandle = <0x42>;

				pins_cmd_dat {
					output-low;
					pins = <0x2c00>;
					slew-rate = <0x1>;
				};
			};

			cam0@1 {
				linux,phandle = <0x43>;
				phandle = <0x43>;

				pins_cmd_dat {
					output-high;
					pins = <0x2c00>;
					slew-rate = <0x1>;
				};
			};

			cam0@2 {
				linux,phandle = <0x44>;
				phandle = <0x44>;

				pins_cmd_dat {
					output-low;
					pins = <0x5e00>;
					slew-rate = <0x1>;
				};
			};

			cam0@3 {
				linux,phandle = <0x45>;
				phandle = <0x45>;

				pins_cmd_dat {
					output-high;
					pins = <0x5e00>;
					slew-rate = <0x1>;
				};
			};

			cam1@0 {
				linux,phandle = <0x46>;
				phandle = <0x46>;

				pins_cmd_dat {
					output-low;
					pins = <0x5200>;
					slew-rate = <0x1>;
				};
			};

			cam1@1 {
				linux,phandle = <0x47>;
				phandle = <0x47>;

				pins_cmd_dat {
					output-high;
					pins = <0x5200>;
					slew-rate = <0x1>;
				};
			};

			cam1@2 {
				linux,phandle = <0x48>;
				phandle = <0x48>;

				pins_cmd_dat {
					output-low;
					pins = <0x5d00>;
					slew-rate = <0x1>;
				};
			};

			cam1@3 {
				linux,phandle = <0x49>;
				phandle = <0x49>;

				pins_cmd_dat {
					output-high;
					pins = <0x5d00>;
					slew-rate = <0x1>;
				};
			};

			cam_avdd@0 {
				linux,phandle = <0x50>;
				phandle = <0x50>;

				pins_cmd_dat {
					output-low;
					pins = <0x7e00>;
					slew-rate = <0x1>;
				};
			};

			cam_avdd@1 {
				linux,phandle = <0x51>;
				phandle = <0x51>;

				pins_cmd_dat {
					output-high;
					pins = <0x7e00>;
					slew-rate = <0x1>;
				};
			};

			cam_dvdd@0 {
				linux,phandle = <0x52>;
				phandle = <0x52>;

				pins_cmd_dat {
					output-low;
					pins = <0x7d00>;
					slew-rate = <0x1>;
				};
			};

			cam_dvdd@1 {
				linux,phandle = <0x53>;
				phandle = <0x53>;

				pins_cmd_dat {
					output-high;
					pins = <0x7d00>;
					slew-rate = <0x1>;
				};
			};

			camdefault {
				linux,phandle = <0x41>;
				phandle = <0x41>;
			};

			clockbuf@1 {
				linux,phandle = <0x15>;
				phandle = <0x15>;

				pins_cmd0_dat {
					pins = <0x6e01>;
				};

				pins_cmd1_dat {
					pins = <0x6f01>;
				};

				pins_cmd2_dat {
					pins = <0x7001>;
				};

				pins_cmd3_dat {
					pins = <0x7101>;
				};

				pins_cmd4_dat {
					pins = <0x7201>;
				};
			};

			clockbuf@2 {
				linux,phandle = <0x16>;
				phandle = <0x16>;

				pins_cmd0_dat {
					pins = <0x6e04>;
				};

				pins_cmd1_dat {
					pins = <0x6f04>;
				};

				pins_cmd2_dat {
					pins = <0x7004>;
				};

				pins_cmd3_dat {
					pins = <0x7104>;
				};

				pins_cmd4_dat {
					pins = <0x7204>;
				};
			};

			default {
				linux,phandle = <0x58>;
				phandle = <0x58>;
			};

			drvvbus_high {
				linux,phandle = <0x38>;
				phandle = <0x38>;

				pins_cmd_dat {
					bias-pull-down = <0x0>;
					output-high;
					pins = <0x5300>;
					slew-rate = <0x1>;
				};
			};

			drvvbus_init {
				linux,phandle = <0x36>;
				phandle = <0x36>;

				pins_cmd_dat {
					bias-pull-down = <0x0>;
					pins = <0x5300>;
					slew-rate = <0x1>;
				};
			};

			drvvbus_low {
				linux,phandle = <0x37>;
				phandle = <0x37>;

				pins_cmd_dat {
					bias-pull-down = <0x0>;
					output-low;
					pins = <0x5300>;
					slew-rate = <0x1>;
				};
			};

			eint0default {
				linux,phandle = <0x5d>;
				phandle = <0x5d>;
			};

			eint0default1 {
				linux,phandle = <0x63>;
				phandle = <0x63>;
			};

			eint@0 {
				linux,phandle = <0x5e>;
				phandle = <0x5e>;

				pins_cmd_dat {
					bias-disable;
					pins = <0xa00>;
					slew-rate = <0x0>;
				};
			};

			eint@2 {
				linux,phandle = <0x64>;
				phandle = <0x64>;

				pins_cmd_dat {
					bias-disable;
					pins = <0x600>;
					slew-rate = <0x0>;
				};
			};

			eint@7 {
				linux,phandle = <0x71>;
				phandle = <0x71>;

				pins_cmd_dat {
					bias-disable;
					pins = <0x700>;
					slew-rate = <0x0>;
				};
			};

			eint@default {
				linux,phandle = <0x70>;
				phandle = <0x70>;
			};

			eintoutput0 {
				linux,phandle = <0x5f>;
				phandle = <0x5f>;

				pins_cmd_dat {
					output-low;
					pins = <0xa00>;
					slew-rate = <0x1>;
				};
			};

			eintoutput1 {
				linux,phandle = <0x60>;
				phandle = <0x60>;

				pins_cmd_dat {
					output-high;
					pins = <0xa00>;
					slew-rate = <0x1>;
				};
			};

			fingerprint_default {
				linux,phandle = <0x6c>;
				phandle = <0x6c>;
			};

			fingerprint_pin_irq {
				linux,phandle = <0x6d>;
				phandle = <0x6d>;

				pins_cmd_dat {
					bias-disable;
					pins = <0x400>;
					slew-rate = <0x0>;
				};
			};

			fingerprint_reset_high {
				linux,phandle = <0x6e>;
				phandle = <0x6e>;

				pins_cmd_dat {
					output-high;
					pins = <0x100>;
					slew-rate = <0x1>;
				};
			};

			fingerprint_reset_low {
				linux,phandle = <0x6f>;
				phandle = <0x6f>;

				pins_cmd_dat {
					output-low;
					pins = <0x100>;
					slew-rate = <0x1>;
				};
			};

			flash_en@0 {
				linux,phandle = <0x4e>;
				phandle = <0x4e>;

				pins_cmd_dat {
					output-low;
					pins = <0x200>;
					slew-rate = <0x1>;
				};
			};

			flash_en@1 {
				linux,phandle = <0x4f>;
				phandle = <0x4f>;

				pins_cmd_dat {
					output-high;
					pins = <0x200>;
					slew-rate = <0x1>;
				};
			};

			flash_mode@0 {
				linux,phandle = <0x4c>;
				phandle = <0x4c>;

				pins_cmd_dat {
					output-low;
					pins = <0x2b00>;
					slew-rate = <0x1>;
				};
			};

			flash_mode@1 {
				linux,phandle = <0x4d>;
				phandle = <0x4d>;

				pins_cmd_dat {
					output-high;
					pins = <0x2b00>;
					slew-rate = <0x1>;
				};
			};

			gpslna@0 {
				linux,phandle = <0x59>;
				phandle = <0x59>;

				pins_cmd_dat {
					bias-disable;
					output-low;
					pins = <0x3d00>;
					slew-rate = <0x0>;
				};
			};

			gpslna@1 {
				linux,phandle = <0x5a>;
				phandle = <0x5a>;

				pins_cmd_dat {
					output-high;
					pins = <0x3d00>;
					slew-rate = <0x1>;
				};
			};

			gpslna@2 {
				linux,phandle = <0x5b>;
				phandle = <0x5b>;

				pins_cmd_dat {
					output-low;
					pins = <0x3d00>;
					slew-rate = <0x1>;
				};
			};

			gyrodefaultcfg {
				linux,phandle = <0x92>;
				phandle = <0x92>;
			};

			gyropincfg {
				linux,phandle = <0x93>;
				phandle = <0x93>;

				pins_cmd_dat {
					bias-pull-down = <0x0>;
					pins = <0x4300>;
					slew-rate = <0x0>;
				};
			};

			iddig_irq_init {
				linux,phandle = <0x35>;
				phandle = <0x35>;

				pins_cmd_dat {
					bias-pull-up = <0x0>;
					pins = <0x1>;
					slew-rate = <0x0>;
				};
			};

			irtx_gpio_led_def@gpio19 {
				linux,phandle = <0x1d>;
				phandle = <0x1d>;

				pins_cmd_dat {
					bias-disable;
					input-schmitt-enable = <0x0>;
					output-high;
					pins = <0x1300>;
					slew-rate = <0x1>;
				};
			};

			irtx_gpio_led_set@gpio19 {
				linux,phandle = <0x1e>;
				phandle = <0x1e>;

				pins_cmd_dat {
					pins = <0x1302>;
				};
			};

			led_rgb_blue@0 {
				linux,phandle = <0x6a>;
				phandle = <0x6a>;

				pins_cmd_dat {
					output-low;
					pins = <0x5c00>;
					slew-rate = <0x1>;
				};
			};

			led_rgb_blue@1 {
				linux,phandle = <0x6b>;
				phandle = <0x6b>;

				pins_cmd_dat {
					output-high;
					pins = <0x5c00>;
					slew-rate = <0x1>;
				};
			};

			led_rgb_green@0 {
				linux,phandle = <0x68>;
				phandle = <0x68>;

				pins_cmd_dat {
					output-low;
					pins = <0x5c00>;
					slew-rate = <0x1>;
				};
			};

			led_rgb_green@1 {
				linux,phandle = <0x69>;
				phandle = <0x69>;

				pins_cmd_dat {
					output-high;
					pins = <0x5c00>;
					slew-rate = <0x1>;
				};
			};

			led_rgb_red@0 {
				linux,phandle = <0x66>;
				phandle = <0x66>;

				pins_cmd_dat {
					output-low;
					pins = <0x5c00>;
					slew-rate = <0x1>;
				};
			};

			led_rgb_red@1 {
				linux,phandle = <0x67>;
				phandle = <0x67>;

				pins_cmd_dat {
					output-high;
					pins = <0x5c00>;
					slew-rate = <0x1>;
				};
			};

			ledrgbdefault {
				linux,phandle = <0x65>;
				phandle = <0x65>;
			};

			lens@0 {
				linux,phandle = <0x4a>;
				phandle = <0x4a>;

				pins_cmd_dat {
					output-low;
					pins = <0x4000>;
					slew-rate = <0x1>;
				};
			};

			lens@1 {
				linux,phandle = <0x4b>;
				phandle = <0x4b>;

				pins_cmd_dat {
					output-high;
					pins = <0x4000>;
					slew-rate = <0x1>;
				};
			};

			mmc0@default {
				linux,phandle = <0x4>;
				phandle = <0x4>;

				pins_clk {
					drive-strength = [02];
				};

				pins_cmd {
					drive-strength = [02];
				};

				pins_dat {
					drive-strength = [02];
				};

				pins_ds {
					drive-strength = [02];
				};

				pins_rst {
					drive-strength = [02];
				};
			};

			mmc0@register_default {
				cmd_edge = [01];
				cmdrddly = [00];
				cmdrrddly = [00];
				dat0rddly = [00];
				dat1rddly = [00];
				dat2rddly = [00];
				dat3rddly = [00];
				dat4rddly = [00];
				dat5rddly = [00];
				dat6rddly = [00];
				dat7rddly = [00];
				datwrddly = [00];
				ett-hs200-cells = <0xc>;
				ett-hs200-default = <0xb0 0x380 0x0 0xb0 0x7c00 0x0 0xb4 0x38 0x1 0x4 0x2 0x0 0xf0 0x1f0000 0x7 0xf0 0x7c00000 0xb 0xb4 0x7 0x1 0xf0 0x1f 0xb 0x4 0x400 0x0 0xf8 0x1f000000 0x7 0xf0 0x1f00 0x9 0x4 0x4 0x0>;
				ett-hs400-cells = <0x8>;
				ett-hs400-default = <0xb0 0x380 0x0 0xb0 0x7c00 0x0 0x188 0x7c 0x2 0x188 0x1f000 0x10 0xb4 0x38 0x1 0x4 0x2 0x0 0xf0 0x1f0000 0x6 0xf0 0x7c00000 0x6>;
				linux,phandle = <0x5>;
				phandle = <0x5>;
				rdata_edge = [01];
				wdata_edge = [01];
			};

			mmc1@ddr50 {
				linux,phandle = <0x9>;
				phandle = <0x9>;

				pins_clk {
					drive-strength = [03];
				};

				pins_cmd {
					drive-strength = [02];
				};

				pins_dat {
					drive-strength = [02];
				};
			};

			mmc1@default {
				linux,phandle = <0x6>;
				phandle = <0x6>;

				pins_clk {
					drive-strength = [03];
				};

				pins_cmd {
					drive-strength = [03];
				};

				pins_dat {
					drive-strength = [03];
				};
			};

			mmc1@register_default {
				cmd_edge = [01];
				cmdrddly = [00];
				cmdrrddly = [00];
				dat0rddly = [00];
				dat1rddly = [00];
				dat2rddly = [00];
				dat3rddly = [00];
				datwrddly = [00];
				linux,phandle = <0xa>;
				phandle = <0xa>;
				rdata_edge = [01];
				wdata_edge = [01];
			};

			mmc1@sdr104 {
				linux,phandle = <0x7>;
				phandle = <0x7>;

				pins_clk {
					drive-strength = [03];
				};

				pins_cmd {
					drive-strength = [02];
				};

				pins_dat {
					drive-strength = [02];
				};
			};

			mmc1@sdr50 {
				linux,phandle = <0x8>;
				phandle = <0x8>;

				pins_clk {
					drive-strength = [03];
				};

				pins_cmd {
					drive-strength = [02];
				};

				pins_dat {
					drive-strength = [02];
				};
			};

			rstoutput0 {
				linux,phandle = <0x61>;
				phandle = <0x61>;

				pins_cmd_dat {
					output-low;
					pins = <0x3e00>;
					slew-rate = <0x1>;
				};
			};

			rstoutput1 {
				linux,phandle = <0x62>;
				phandle = <0x62>;

				pins_cmd_dat {
					output-high;
					pins = <0x3e00>;
					slew-rate = <0x1>;
				};
			};

			ssw0default {
				linux,phandle = <0x79>;
				phandle = <0x79>;
			};

			ssw@1 {
				linux,phandle = <0x7a>;
				phandle = <0x7a>;

				pins_cmd0_dat {
					pins = <0x805>;
				};

				pins_cmd1_dat {
					pins = <0x904>;
				};
			};

			ssw@2 {
				linux,phandle = <0x7b>;
				phandle = <0x7b>;

				pins_cmd0_dat {
					pins = <0x802>;
				};

				pins_cmd1_dat {
					pins = <0x904>;
				};
			};

			ssw@3 {
				linux,phandle = <0x7c>;
				phandle = <0x7c>;

				pins_cmd0_dat {
					pins = <0xa301>;
					slew-rate = <0x1>;
				};

				pins_cmd1_dat {
					pins = <0xa401>;
					slew-rate = <0x1>;
				};

				pins_cmd2_dat {
					bias-pull-up = <0x0>;
					pins = <0xa501>;
					slew-rate = <0x0>;
				};

				pins_cmd3_dat {
					pins = <0xa001>;
					slew-rate = <0x1>;
				};

				pins_cmd4_dat {
					pins = <0xa101>;
					slew-rate = <0x1>;
				};

				pins_cmd5_dat {
					bias-pull-up = <0x0>;
					pins = <0xa201>;
					slew-rate = <0x0>;
				};
			};

			ssw@4 {
				linux,phandle = <0x7d>;
				phandle = <0x7d>;

				pins_cmd0_dat {
					pins = <0xa304>;
				};

				pins_cmd1_dat {
					pins = <0xa404>;
				};

				pins_cmd2_dat {
					pins = <0xa504>;
				};

				pins_cmd3_dat {
					pins = <0xa001>;
				};

				pins_cmd4_dat {
					pins = <0xa101>;
				};

				pins_cmd5_dat {
					pins = <0xa201>;
				};
			};

			state_eint_high {
				linux,phandle = <0x76>;
				phandle = <0x76>;

				pins_cmd_dat {
					output-high;
					pins = <0x100>;
					slew-rate = <0x1>;
				};
			};

			state_eint_low {
				linux,phandle = <0x77>;
				phandle = <0x77>;

				pins_cmd_dat {
					output-low;
					pins = <0x100>;
					slew-rate = <0x1>;
				};
			};

			state_irq_init {
				linux,phandle = <0x78>;
				phandle = <0x78>;

				pins_cmd_dat {
					bias-pull-down = <0x0>;
					pins = <0x200>;
					slew-rate = <0x0>;
				};
			};

			state_rst_high {
				linux,phandle = <0x74>;
				phandle = <0x74>;

				pins_cmd_dat {
					output-high;
					pins = <0x300>;
					slew-rate = <0x1>;
				};
			};

			state_rst_low {
				linux,phandle = <0x75>;
				phandle = <0x75>;

				pins_cmd_dat {
					output-low;
					pins = <0x300>;
					slew-rate = <0x1>;
				};
			};

			state_ven_high {
				linux,phandle = <0x72>;
				phandle = <0x72>;

				pins_cmd_dat {
					output-high;
					pins = <0x400>;
					slew-rate = <0x1>;
				};
			};

			state_ven_low {
				linux,phandle = <0x73>;
				phandle = <0x73>;

				pins_cmd_dat {
					output-low;
					pins = <0x400>;
					slew-rate = <0x1>;
				};
			};

			uart0_rx_clear@gpio74 {
				linux,phandle = <0x21>;
				phandle = <0x21>;

				pins_cmd_dat {
					output-high;
					pins = <0x4a00>;
					slew-rate = <0x1>;
				};
			};

			uart0_rx_set@gpio74 {
				linux,phandle = <0x20>;
				phandle = <0x20>;

				pins_cmd_dat {
					pins = <0x4a01>;
				};
			};

			uart0_tx_clear@gpio75 {
				linux,phandle = <0x23>;
				phandle = <0x23>;

				pins_cmd_dat {
					output-high;
					pins = <0x4b00>;
					slew-rate = <0x1>;
				};
			};

			uart0_tx_set@gpio75 {
				linux,phandle = <0x22>;
				phandle = <0x22>;

				pins_cmd_dat {
					pins = <0x4b01>;
				};
			};

			uart0gpiodefault {
				linux,phandle = <0x1f>;
				phandle = <0x1f>;
			};

			uart1_rx_clear@gpio76 {
				linux,phandle = <0x26>;
				phandle = <0x26>;

				pins_cmd_dat {
					output-high;
					pins = <0x4c00>;
					slew-rate = <0x1>;
				};
			};

			uart1_rx_set@gpio76 {
				linux,phandle = <0x25>;
				phandle = <0x25>;

				pins_cmd_dat {
					pins = <0x4c01>;
				};
			};

			uart1_tx_clear@gpio77 {
				linux,phandle = <0x28>;
				phandle = <0x28>;

				pins_cmd_dat {
					output-high;
					pins = <0x4d00>;
					slew-rate = <0x1>;
				};
			};

			uart1_tx_set@gpio77 {
				linux,phandle = <0x27>;
				phandle = <0x27>;

				pins_cmd_dat {
					pins = <0x4d01>;
				};
			};

			uart1gpiodefault {
				linux,phandle = <0x24>;
				phandle = <0x24>;
			};

			uart2_rx_clear@gpio57 {
				linux,phandle = <0x2b>;
				phandle = <0x2b>;

				pins_cmd_dat {
					output-high;
					pins = <0x3900>;
					slew-rate = <0x1>;
				};
			};

			uart2_rx_set@gpio57 {
				linux,phandle = <0x2a>;
				phandle = <0x2a>;

				pins_cmd_dat {
					pins = <0x3901>;
				};
			};

			uart2_tx_clear@gpio58 {
				linux,phandle = <0x2d>;
				phandle = <0x2d>;

				pins_cmd_dat {
					output-high;
					pins = <0x3a00>;
					slew-rate = <0x1>;
				};
			};

			uart2_tx_set@gpio58 {
				linux,phandle = <0x2c>;
				phandle = <0x2c>;

				pins_cmd_dat {
					pins = <0x3a01>;
				};
			};

			uart2gpiodefault {
				linux,phandle = <0x29>;
				phandle = <0x29>;
			};

			uart3_rx_clear@gpio59 {
				linux,phandle = <0x30>;
				phandle = <0x30>;

				pins_cmd_dat {
					output-high;
					pins = <0x3b00>;
					slew-rate = <0x1>;
				};
			};

			uart3_rx_set@gpio59 {
				linux,phandle = <0x2f>;
				phandle = <0x2f>;

				pins_cmd_dat {
					pins = <0x3b01>;
				};
			};

			uart3_tx_clear@gpio60 {
				linux,phandle = <0x32>;
				phandle = <0x32>;

				pins_cmd_dat {
					output-high;
					pins = <0x3c00>;
					slew-rate = <0x1>;
				};
			};

			uart3_tx_set@gpio60 {
				linux,phandle = <0x31>;
				phandle = <0x31>;

				pins_cmd_dat {
					pins = <0x3c01>;
				};
			};

			uart3gpiodefault {
				linux,phandle = <0x2e>;
				phandle = <0x2e>;
			};

			usb_default {
				linux,phandle = <0x34>;
				phandle = <0x34>;
			};

			vsram0default {
				linux,phandle = <0x12>;
				phandle = <0x12>;
			};

			vsram@1 {
				linux,phandle = <0x13>;
				phandle = <0x13>;

				pins_cmd_dat {
					output-low;
					pins = <0x8c00>;
					slew-rate = <0x1>;
				};
			};

			vsram@2 {
				linux,phandle = <0x14>;
				phandle = <0x14>;

				pins_cmd_dat {
					output-high;
					pins = <0x8c00>;
					slew-rate = <0x1>;
				};
			};
		};

		ptp_fsm@1100b000 {
			compatible = "mediatek,ptp_fsm_v1";
			interrupts = <0x0 0x7d 0x8>;
			reg = <0x1100b000 0x1000>;
		};

		pwm@11006000 {
			clock-names = "PWM-main", "PWM1-main", "PWM2-main", "PWM3-main", "PWM4-main", "PWM5-main";
			clocks = <0x2 0xa 0x2 0x3 0x2 0x4 0x2 0x5 0x2 0x6 0x2 0x7>;
			compatible = "mediatek,pwm";
			interrupts = <0x0 0x4d 0x8>;
			reg = <0x11006000 0x1000>;
		};

		pwrap@10001000 {
			compatible = "mediatek,PWRAP";
			interrupts = <0x0 0xa3 0x4>;
			reg = <0x10001000 0x1000>;
		};

		scpsys@10000000 {
			#clock-cells = <0x1>;
			compatible = "mediatek,mt6735-scpsys";
			linux,phandle = <0x11>;
			phandle = <0x11>;
			reg = <0x10000000 0x1000 0x10006000 0x1000>;
		};

		simswitch {
			compatible = "mediatek,sim_switch";
			pinctrl-0 = <0x79>;
			pinctrl-1 = <0x7a>;
			pinctrl-2 = <0x7b>;
			pinctrl-3 = <0x7c>;
			pinctrl-4 = <0x7d>;
			pinctrl-names = "default", "hot_plug_mode1", "hot_plug_mode2", "two_sims_bound_to_md1", "sim1_md3_sim2_md1";
		};

		sleep@10006000 {
			compatible = "mediatek,sleep";
			interrupts = <0x0 0xa5 0x8 0x0 0xa6 0x8 0x0 0xa7 0x8 0x0 0xa8 0x8>;
			reg = <0x10006000 0x1000>;
		};

		smi_common@14016000 {
			clock-names = "smi-common", "smi-larb0", "img-larb2", "vdec0-vdec", "vdec1-larb", "venc-larb", "venc-venc", "mtcmos-ven", "mtcmos-vde", "mtcmos-isp", "mtcmos-dis";
			clocks = <0x18 0x1 0x18 0x2 0x1a 0x1 0x19 0x1 0x19 0x2 0x1b 0x1 0x1b 0x2 0x11 0x8 0x11 0x7 0x11 0x6 0x11 0x4>;
			compatible = "mediatek,smi_common";
			reg = <0x14016000 0x1000 0x14015000 0x1000 0x16010000 0x1000 0x15001000 0x1000 0x17001000 0x1000>;
		};

		smi_larb0@14015000 {
			compatible = "mediatek,smi_larb0";
			reg = <0x14015000 0x1000>;
		};

		smi_larb1@16010000 {
			compatible = "mediatek,smi_larb1";
			interrupts = <0x0 0xb1 0x8>;
			reg = <0x16010000 0x1000>;
		};

		smi_larb2@15001000 {
			compatible = "mediatek,smi_larb2";
			interrupts = <0x0 0xb2 0x8>;
			reg = <0x15001000 0x1000>;
		};

		smi_larb3@17001000 {
			compatible = "mediatek,smi_larb3";
			interrupts = <0x0 0xca 0x8>;
			reg = <0x17001000 0x1000>;
		};

		spi@1100a000 {
			cell-index = <0x0>;
			clock-div = <0x1>;
			clock-frequency = <0x67f3540>;
			clock-names = "spi-main";
			clocks = <0x2 0x1d>;
			compatible = "mediatek,mt6735-spi";
			interrupts = <0x0 0x76 0x8>;
			reg = <0x1100a000 0x1000>;
			spi-padmacro = <0x0>;
		};

		sys_cirq@10204000 {
			compatible = "mediatek,mt6735-sys_cirq";
			interrupts = <0x0 0xe7 0x8>;
			mediatek,cirq_num = <0x9f>;
			mediatek,spi_start_offset = <0x48>;
			reg = <0x10204000 0x1000>;
		};

		syscfg_pctl_a@10211000 {
			compatible = "mediatek,mt6735-pctl-a-syscfg", "syscon";
			linux,phandle = <0x1c>;
			phandle = <0x1c>;
			reg = <0x0 0x9bceb8 0x0 0x3e8>;
		};

		therm_ctrl@1100b000 {
			clock-names = "therm-main";
			clocks = <0x2 0x2>;
			compatible = "mediatek,mt6735-therm_ctrl";
			interrupts = <0x0 0x4e 0x8>;
			reg = <0x1100b000 0x1000>;
		};

		timer {
			clock-frequency = <0xc65d40>;
			compatible = "arm,armv8-timer";
			interrupts = <0x1 0xd 0x8 0x1 0xe 0x8 0x1 0xb 0x8 0x1 0xa 0x8>;
		};

		topckgen@10210000 {
			#clock-cells = <0x1>;
			compatible = "mediatek,mt6735-topckgen";
			linux,phandle = <0x3>;
			phandle = <0x3>;
			reg = <0x10210000 0x1000>;
		};

		toprgu@10212000 {
			compatible = "mediatek,mt6735-rgu";
			interrupts = <0x0 0x80 0x2>;
			reg = <0x10212000 0x1000>;
		};

		touch {
			compatible = "mediatek,mt6735-touch";
			debounce = <0xa 0x0>;
			interrupt-parent = <0xc>;
			interrupts = <0xa 0x2>;
			pinctrl-0 = <0x5d>;
			pinctrl-1 = <0x5e>;
			pinctrl-2 = <0x5f>;
			pinctrl-3 = <0x60>;
			pinctrl-4 = <0x61>;
			pinctrl-5 = <0x62>;
			pinctrl-names = "default", "state_eint_as_int", "state_eint_output0", "state_eint_output1", "state_rst_output0", "state_rst_output1";
			status = "okay";
			tpd-filter-custom-prameters = <0x0 0x0 0x0 0x0 0x0 0x0 0x0 0x0 0x0 0x0 0x0 0x0>;
			tpd-filter-custom-speed = <0x0 0x0 0x0>;
			tpd-filter-enable = <0x1>;
			tpd-filter-pixel-density = <0x7c>;
			tpd-key-dim-local = <0x78 0x564 0x64 0x28 0x168 0x564 0x64 0x28 0x258 0x564 0x64 0x28 0x0 0x0 0x0 0x0>;
			tpd-key-local = <0x8b 0xac 0x9e 0x0>;
			tpd-key-num = <0x3>;
			tpd-max-touch-num = <0x5>;
			tpd-resolution = <0x2d0 0x500>;
			use-tpd-button = <0x1>;
			vtouch-supply = <0x5c>;
		};

		usb20@11200000 {
			cell-index = <0x0>;
			clock-names = "usb0";
			clocks = <0x2 0xb>;
			compatible = "mediatek,mt6735-usb20";
			drvvbus_gpio = <0x53 0x2>;
			iddig_gpio = <0x0 0x1>;
			interrupts = <0x0 0x48 0x8>;
			mode = <0x2>;
			multipoint = <0x1>;
			num_eps = <0x10>;
			pinctrl-0 = <0x34>;
			pinctrl-1 = <0x35>;
			pinctrl-2 = <0x36>;
			pinctrl-3 = <0x37>;
			pinctrl-4 = <0x38>;
			pinctrl-names = "usb_default", "iddig_irq_init", "drvvbus_init", "drvvbus_low", "drvvbus_high";
			reg = <0x11200000 0x10000 0x11210000 0x10000>;
			status = "okay";
			vusb33-supply = <0x33>;
		};

		vdec@16020000 {
			compatible = "mediatek,mt6735-vdec";
			interrupts = <0x0 0xb3 0x8>;
			reg = <0x16020000 0x10000>;
		};

		vdec_gcon@16000000 {
			clock-names = "MT_CG_DISP0_SMI_COMMON", "MT_CG_VDEC0_VDEC", "MT_CG_VDEC1_LARB", "MT_CG_VENC_VENC", "MT_CG_VENC_LARB", "MT_CG_TOP_MUX_VDEC", "MT_CG_TOP_SYSPLL1_D2", "MT_CG_TOP_SYSPLL1_D4", "MT_SCP_SYS_VDE", "MT_SCP_SYS_VEN", "MT_SCP_SYS_DIS";
			clocks = <0x18 0x1 0x19 0x1 0x19 0x2 0x1b 0x2 0x1b 0x1 0x3 0x6 0x3 0x32 0x3 0x33 0x11 0x7 0x11 0x8 0x11 0x4>;
			compatible = "mediatek,mt6735-vdec_gcon";
			interrupts = <0x0 0xb3 0x8>;
			reg = <0x16000000 0x1000>;
		};

		vdecsys@16000000 {
			#clock-cells = <0x1>;
			compatible = "mediatek,mt6735-vdecsys";
			interrupts = <0x0 0xb3 0x8>;
			linux,phandle = <0x19>;
			phandle = <0x19>;
			reg = <0x16000000 0x1000>;
		};

		venc@17002000 {
			compatible = "mediatek,mt6735-venc";
			interrupts = <0x0 0xb4 0x8>;
			reg = <0x17002000 0x1000>;
		};

		venc_gcon@17000000 {
			compatible = "mediatek,mt6735-venc_gcon";
			interrupts = <0x0 0xb4 0x8>;
			reg = <0x17000000 0x1000>;
		};

		vencsys@17000000 {
			#clock-cells = <0x1>;
			compatible = "mediatek,mt6735-vencsys";
			interrupts = <0x0 0xb4 0x8>;
			linux,phandle = <0x1b>;
			phandle = <0x1b>;
			reg = <0x17000000 0x1000>;
		};

		wifi@180f0000 {
			clock-names = "wifi-dma";
			clocks = <0x2 0xd>;
			compatible = "mediatek,wifi";
			interrupts = <0x0 0xe2 0x8>;
			reg = <0x180f0000 0x5c>;
		};
	};

	trusty {
		#address-cells = <0x2>;
		#size-cells = <0x2>;
		compatible = "android,trusty-smc-v1";
		ranges;

		irq {
			compatible = "android,trusty-irq-v1";
		};

		log {
			compatible = "android,trusty-log-v1";
		};

		virtio {
			compatible = "android,trusty-virtio-v1";
		};
	};

	vcorefs {
		clock-names = "mux_axi", "syspll_d5", "syspll1_d4";
		clocks = <0x3 0x1 0x3 0x30 0x3 0x33>;
		compatible = "mediatek,mt6735-vcorefs";
	};

	vibrator@0 {
		compatible = "mediatek,vibrator";
		vib_limit = <0x9>;
		vib_timer = <0x19>;
		vib_vol = <0x5>;
	};
};
